VERSION ""

NS_ :

BS_:
BU_: Audio_Control_Module Audio_Interface_Module Bluetooth_Phone_Module Body_Electric_Module Front_Display_Interface_Module HVAC_Integrated_Module Instrustment_Cluster Parking_Aid_Module Powertrain_Control_Module Restraints_Control_Module Transmission_Control_Module On_Board_Diagnostics Antilock_Braking_System
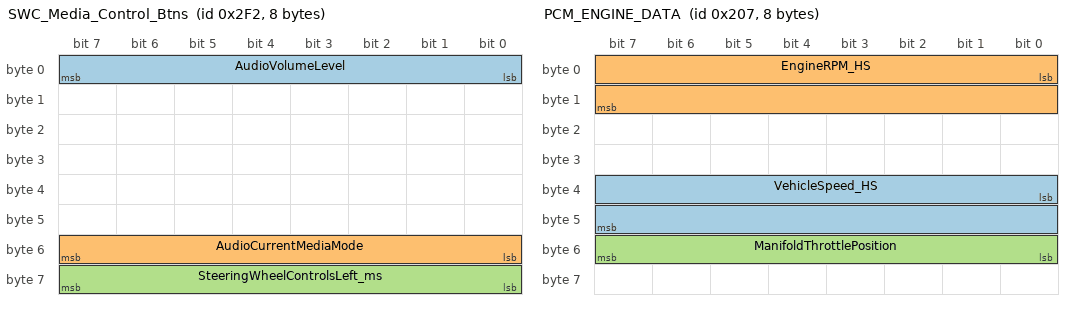
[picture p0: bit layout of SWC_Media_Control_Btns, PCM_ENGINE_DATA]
BO_ 754 SWC_Media_Control_Btns: 8 Front_Display_Interface_Module
   SG_ AudioVolumeLevel : 0|8@1+ (2,0) [0|15] "Vol" Audio_Control_Module
   SG_ AudioCurrentMediaMode : 48|8@1+ (1,0) [0|0] "" Audio_Control_Module
   SG_ SteeringWheelControlsLeft_ms : 56|8@1+ (1,0) [0|255] "ACTIVE/INACTIVE" Front_Display_Interface_Module

BO_ 764 Interior_Command_Centre_Btns: 8 Front_Display_Interface_Module
   SG_ SIGNAL38877 : 29|8@1+ (1,0) [0|255] "" Body_Electric_Module
   SG_ SIGNAL3887752 : 16|8@1+ (1,0) [0|255] "" Body_Electric_Module
   SG_ SIGNAL38877522 : 24|8@1+ (1,0) [0|255] "" Body_Electric_Module
   SG_ SIGNAL3887752238 : 8|8@1+ (1,0) [0|255] "" Body_Electric_Module

BO_ 751 MSG4: 8 Audio_Control_Module

BO_ 756 RDS_MESSAGE: 8 Audio_Control_Module
   SG_ RDS_MESSAGE0 : 0|8@4- (1,0) [0|255] "" Front_Display_Interface_Module
   SG_ RDS_MESSAGE1 : 8|8@4- (1,0) [0|255] "" Front_Display_Interface_Module
   SG_ RDS_MESSAGE2 : 16|8@4- (1,0) [0|255] "" Front_Display_Interface_Module
   SG_ RDS_MESSAGE3 : 24|8@4- (1,0) [0|255] "" Front_Display_Interface_Module
   SG_ RDS_MESSAGE4 : 32|8@4- (1,0) [0|255] "" Front_Display_Interface_Module
   SG_ RDS_MESSAGE5 : 40|8@4- (1,0) [0|255] "" Front_Display_Interface_Module
   SG_ RDS_MESSAGE6 : 48|8@4- (1,0) [0|255] "" Front_Display_Interface_Module
   SG_ RDS_MESSAGE7 : 56|8@4- (1,0) [0|255] "" Front_Display_Interface_Module

BO_ 757 RDS__MESSAGE: 8 Audio_Control_Module
   SG_ RDS_MESSAGE0 : 0|8@4- (1,0) [0|255] "" Front_Display_Interface_Module
   SG_ RDS_MESSAGE1 : 8|8@4- (1,0) [0|255] "" Front_Display_Interface_Module
   SG_ RDS_MESSAGE2 : 16|8@4- (1,0) [0|255] "" Front_Display_Interface_Module
   SG_ RDS_MESSAGE3 : 24|8@4- (1,0) [0|255] "" Front_Display_Interface_Module
   SG_ RDS_MESSAGE4 : 32|8@4- (1,0) [0|255] "" Front_Display_Interface_Module
   SG_ RDS_MESSAGE5 : 40|8@4- (1,0) [0|255] "" Front_Display_Interface_Module
   SG_ RDS_MESSAGE6 : 48|8@4- (1,0) [0|255] "" Front_Display_Interface_Module
   SG_ RDS_MESSAGE7 : 56|8@4- (1,0) [0|255] "" Front_Display_Interface_Module

BO_ 512 CrankStatusPCM_HS: 8 Powertrain_Control_Module
   SG_ CrankStatusPCM_HS : 0|8@1+ (1,0) [0|0] "" Powertrain_Control_Module

BO_ 519 PCM_ENGINE_DATA: 8 Powertrain_Control_Module
   SG_ VehicleSpeed_HS : 32|16@1+ (0.25,255) [0|260] "KM/H" Instrustment_Cluster
   SG_ EngineRPM_HS : 0|16@1+ (1,255) [0|8000] "RPM" Powertrain_Control_Module
   SG_ ManifoldThrottlePosition : 48|8@1+ (1,0) [0|100] "%" Powertrain_Control_Module

BO_ 528 ABS_DSC: 8 Antilock_Braking_System
   SG_ DSC : 16|8@1+ (1,0) [0|0] "" Antilock_Braking_System
   SG_ VDC_Failed : 0|8@1+ (1,0) [0|0] "" Antilock_Braking_System
   SG_ VDC_Event : 0|1@1+ (1,0) [0|0] "" Antilock_Braking_System
   SG_ VDC_DisabledByOperator : 24|1@1+ (1,0) [0|0] "" Antilock_Braking_System

BO_ 0 ABS_DSC: 8 Antilock_Braking_System
   SG_ ABSLF_I : 16|8@1+ (1,0) [0|0] "" Antilock_Braking_System
   SG_ ABSLF_I : 16|8@1+ (1,0) [0|0] "" Vector__XXX
   SG_ ABSLF_O : 16|8@1+ (1,0) [0|0] "" Vector__XXX
   SG_ ABSLR_I : 16|8@1+ (1,0) [0|0] "" Vector__XXX
   SG_ ABSLR_O : 16|8@1+ (1,0) [0|0] "" Vector__XXX
   SG_ ABSPMPRLY : 16|8@1+ (1,0) [0|0] "" Vector__XXX
   SG_ ABSRF_I : 16|8@1+ (1,0) [0|0] "" Vector__XXX
   SG_ ABSRF_O : 16|8@1+ (1,0) [0|0] "" Vector__XXX
   SG_ ABSRR_I : 16|8@1+ (1,0) [0|0] "" Vector__XXX
   SG_ ABSR_I : 16|8@1+ (1,0) [0|0] "" Vector__XXX
   SG_ ABSR_O : 16|8@1+ (1,0) [0|0] "" Vector__XXX
   SG_ ABSVLVRLY : 16|8@1+ (1,0) [0|0] "" Vector__XXX
   SG_ ABS_BYTE : 16|8@1+ (1,0) [0|0] "" Vector__XXX
   SG_ ABS_STAT : 16|8@1+ (1,0) [0|0] "" Vector__XXX
   SG_ BOO_ABS : 16|8@1+ (1,0) [0|0] "" Vector__XXX
   SG_ BRAKPRES : 16|8@1+ (1,0) [0|0] "" Vector__XXX
   SG_ CCNTABS : 16|8@1+ (1,0) [0|0] "" Vector__XXX
   SG_ DISABLE_SS : 16|8@1+ (1,0) [0|0] "" Vector__XXX
   SG_ HDC_ENABLE : 16|8@1+ (1,0) [0|0] "" Vector__XXX
   SG_ HDC_SW : 16|8@1+ (1,0) [0|0] "" Vector__XXX
   SG_ Ignition : 16|8@1+ (1,0) [0|0] "" Vector__XXX
   SG_ LAT_ACCL : 16|8@1+ (1,0) [0|0] "" Vector__XXX
   SG_ LF_WSPD : 16|8@1+ (1,0) [0|0] "" Vector__XXX
   SG_ LR_WSPD : 16|8@1+ (1,0) [0|0] "" Vector__XXX
   SG_ PMPSTAT : 16|8@1+ (1,0) [0|0] "" Vector__XXX
   SG_ PRK_BRAKE : 16|8@1+ (1,0) [0|0] "" Vector__XXX
   SG_ RF_WSPD : 16|8@1+ (1,0) [0|0] "" Vector__XXX
   SG_ RR_WSPD : 16|8@1+ (1,0) [0|0] "" Vector__XXX
   SG_ STEER_ANGL : 16|8@1+ (1,0) [0|0] "" Vector__XXX
   SG_ TCSPRI1 : 16|8@1+ (1,0) [0|0] "" Vector__XXX
   SG_ TCSPRI2 : 16|8@1+ (1,0) [0|0] "" Vector__XXX
   SG_ TCSSWI1 : 16|8@1+ (1,0) [0|0] "" Vector__XXX
   SG_ TCSSWI2 : 16|8@1+ (1,0) [0|0] "" Vector__XXX
   SG_ TCYC_FS : 16|8@1+ (1,0) [0|0] "" Vector__XXX
   SG_ TCYC_SW : 16|8@1+ (1,0) [0|0] "" Vector__XXX
   SG_ YAW_RATE : 16|8@1+ (1,0) [0|0] "" Vector__XXX

BO_ 560 TRANS: 8 Powertrain_Control_Module

BO_ 787 INTACTTEMP: 8 HVAC_Integrated_Module
   SG_ INTACTTEMP : 7|8@0+ (0.166667,0) [0|255] "Degrees_C" HVAC_Integrated_Module

BO_ 737 MSG1: 8 Front_Display_Interface_Module

BO_ 739 MSG2: 8 Front_Display_Interface_Module

BO_ 748 MSG3: 8 Front_Display_Interface_Module

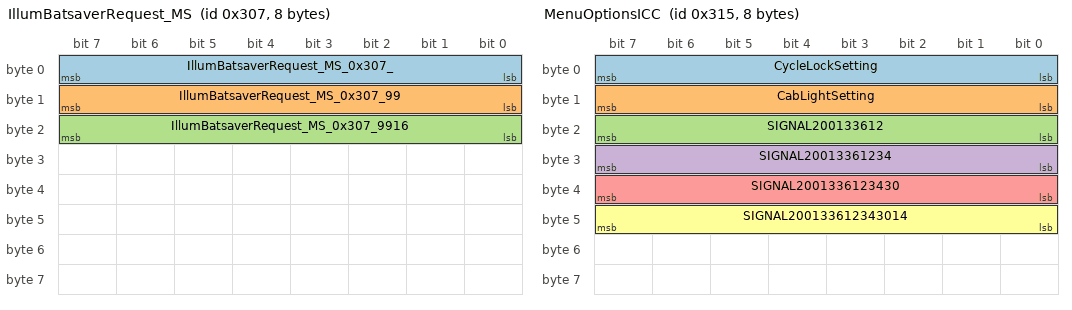
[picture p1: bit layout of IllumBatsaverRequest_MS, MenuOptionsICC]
BO_ 775 IllumBatsaverRequest_MS: 8 Body_Electric_Module
   SG_ IllumBatsaverRequest_MS_0x307_ : 0|8@1+ (1,0) [0|255] "" Body_Electric_Module
   SG_ IllumBatsaverRequest_MS_0x307_99 : 8|8@1+ (1,0) [0|0] "" Body_Electric_Module
   SG_ IllumBatsaverRequest_MS_0x307_9916 : 16|8@1+ (1,0) [0|255] "" Body_Electric_Module

BO_ 779 MSG6: 8 Body_Electric_Module

BO_ 781 CD_TRACK_TYPE_PLAYING: 8 Audio_Control_Module
   SG_ CD_TrackNumber : 0|8@1+ (1,0) [0|0] "" Front_Display_Interface_Module
   SG_ CD_Type : 0|8@1+ (1,0) [0|0] "" Front_Display_Interface_Module
   SG_ CD_PlayingNow : 0|8@1+ (1,0) [0|0] "" Front_Display_Interface_Module

BO_ 783 MSG8: 8 Body_Electric_Module

BO_ 785 MSG9: 8 Body_Electric_Module

BO_ 789 MenuOptionsICC: 8 Front_Display_Interface_Module
   SG_ CycleLockSetting : 0|8@1+ (1,0) [0|255] "" Front_Display_Interface_Module
   SG_ CabLightSetting : 8|8@1+ (1,0) [0|255] "" Front_Display_Interface_Module
   SG_ SIGNAL200133612 : 16|8@1+ (1,0) [0|255] "" Front_Display_Interface_Module
   SG_ SIGNAL20013361234 : 24|8@1+ (1,0) [0|255] "" Front_Display_Interface_Module
   SG_ SIGNAL2001336123430 : 32|8@1+ (1,0) [0|255] "" Front_Display_Interface_Module
   SG_ SIGNAL200133612343014 : 40|8@1+ (1,0) [0|255] "" Front_Display_Interface_Module

BO_ 791 VehicleIdentificationNumber: 8 Body_Electric_Module
   SG_ SIGNAL64904 : 0|8@1+ (1,0) [0|0] "" Body_Electric_Module
   SG_ SIGNAL11010 : 8|8@1+ (1,0) [0|0] "" Vector__XXX
   SG_ SIGNAL11074 : 8|8@1+ (1,0) [0|0] "" Vector__XXX
   SG_ SIGNAL61769 : 0|1@1+ (1,0) [0|0] "" Vector__XXX
   SG_ SIGNAL110107498 : 8|8@1+ (1,0) [0|0] "" Vector__XXX

BO_ 816 ParkBrakeOn_MS: 8 Body_Electric_Module
   SG_ ParkBrakeOn_MS : 0|8@1+ (1,0) [0|0] "" Body_Electric_Module

BO_ 1030 SeatBeltStatus: 8 Body_Electric_Module
   SG_ SeatBeltStatusFrontRight : 0|8@1+ (1,0) [0|0] "" Instrustment_Cluster
   SG_ SeatBeltStatusFrontLeft : 32|8@1+ (1,0) [0|0] "" Instrustment_Cluster
   SG_ SeatBeltStatusRearLeft : 16|8@1+ (1,0) [0|0] "" Instrustment_Cluster
   SG_ SeatBeltStatusRearRight : 24|8@1+ (1,0) [0|0] "" Instrustment_Cluster
   SG_ IgnitionState : 8|8@1+ (1,0) [0|0] "" Body_Electric_Module
   SG_ InteriorLightStatus : 0|8@1+ (1,0) [0|0] "" Body_Electric_Module

BO_ 1033 MSG14: 8 Body_Electric_Module

BO_ 1281 MSG15: 8 Body_Electric_Module

BO_ 1292 ACM_KeepAlive: 8 Audio_Control_Module

BO_ 1297 MSG17: 8 Body_Electric_Module

BO_ 1345 MSG18: 8 Body_Electric_Module

BO_ 1365 MSG19: 8 Body_Electric_Module

BO_ 1372 FDIM_KeepAlive: 8 Front_Display_Interface_Module

BO_ 1600 ManualTrans: 8 Body_Electric_Module
   SG_ ManualTrans : 0|8@1+ (1,0) [0|255] "" Instrustment_Cluster

BO_ 1782 ImmobTransfer_PCM_1_to_8_PATS: 8 Body_Electric_Module
   SG_ ImmobTransfer_PCM_1_to_8_PATS : 0|63@4- (1,0) [0|0] "" Body_Electric_Module

BO_ 1788 MSG23: 8 Body_Electric_Module

BO_ 301 EngineManagementData: 8 Powertrain_Control_Module
   SG_ AcceleratorPedalPosition1 : 8|8@1+ (0.5,0) [0|200] "%" Powertrain_Control_Module
   SG_ EngineRateOfChange0 : 0|8@1+ (1,0) [0|255] "" Powertrain_Control_Module
   SG_ AcceleratorPedalPosition2 : 16|8@1+ (0.5,0) [0|200] "%" Powertrain_Control_Module
   SG_ EngineRevolutionsPerMinute5 : 40|8@1+ (0.5,0) [0|0] "RPM" Powertrain_Control_Module
   SG_ EngineRevolutionsPerMinute4 : 32|8@1+ (1,255) [0|0] "RPM" Powertrain_Control_Module
   SG_ Flags : 48|8@1+ (1,0) [0|0] "" Powertrain_Control_Module
   SG_ BrakeHardwareStatus : 0|8@1+ (1,0) [0|1] "" Powertrain_Control_Module

BO_ 288 MSG1: 8 Powertrain_Control_Module
   SG_ TorqueReductionRequest : 0|8@1+ (1,0) [0|0] "" Powertrain_Control_Module

BO_ 1001 MSG2: 8 Powertrain_Control_Module

BO_ 1031 MSG3: 8 Powertrain_Control_Module

BO_ 1061 PCM_CRS_ECON: 8 Powertrain_Control_Module
   SG_ Cruise : 0|1@1+ (1,0) [0|0] "" Powertrain_Control_Module
   SG_ CruiseTargetSetSpeed : 0|1@1+ (1,0) [0|0] "" Powertrain_Control_Module
   SG_ InstantEconomy : 0|1@1+ (1,0) [0|0] "" Powertrain_Control_Module
   SG_ InstantEconomyMode : 0|1@1+ (1,0) [0|0] "" Powertrain_Control_Module
   SG_ TurboBoostPressure : 0|1@1+ (1,0) [0|0] "" Powertrain_Control_Module

BO_ 1063 PCM_ENGINE_DATA: 8 Powertrain_Control_Module
   SG_ EngineCoolantTemperature : 0|8@1+ (0.5,0) [0|255] "Degrees_C" Powertrain_Control_Module
   SG_ EngineOverheat : 40|8@1+ (1,0) [0|0] "" Powertrain_Control_Module
   SG_ OilPressureWarning : 40|8@1+ (1,0) [0|0] "" Powertrain_Control_Module
   SG_ ETC_Warning : 40|8@1+ (1,0) [0|0] "" Powertrain_Control_Module
   SG_ FuelPulse : 0|1@1+ (1,0) [0|0] "" Powertrain_Control_Module
   SG_ MIL_Lamp : 40|8@1+ (1,0) [0|0] "" Powertrain_Control_Module
   SG_ AC_Pressure : 8|16@1+ (1,0) [0|255] "KPa" Powertrain_Control_Module
   SG_ ImmobLamp : 48|8@1+ (1,0) [0|0] "" Powertrain_Control_Module
   SG_ SEATBELT_INDICATOR_STAT : 48|8@1+ (1,0) [0|0] "" Powertrain_Control_Module
   SG_ ODO_COUNT : 32|8@1+ (1,0) [0|255] "" Powertrain_Control_Module
   SG_ BatteryVoltage : 24|8@1+ (0.1,0) [0|255] "Volts" Body_Electric_Module
   SG_ EngineSpeedCounter : 56|8@1+ (1,0) [0|255] "Count" Powertrain_Control_Module

BO_ 1079 PCM_: 8 Powertrain_Control_Module
   SG_ InstFuelValue : 0|1@1+ (1,0) [0|0] "" Powertrain_Control_Module
   SG_ FuelSenderFail : 0|1@1+ (1,0) [0|0] "" Powertrain_Control_Module
   SG_ ParkBrakeOn_HS : 32|1@1+ (1,0) [0|0] "" Powertrain_Control_Module
   SG_ MaxLitres : 0|1@1+ (1,0) [0|0] "" Powertrain_Control_Module
   SG_ DampedFuelLevel : 0|1@1+ (1,0) [0|0] "" Powertrain_Control_Module

BO_ 1101 PCM_EOT_: 8 Powertrain_Control_Module

BO_ 1107 ODO: 8 Powertrain_Control_Module

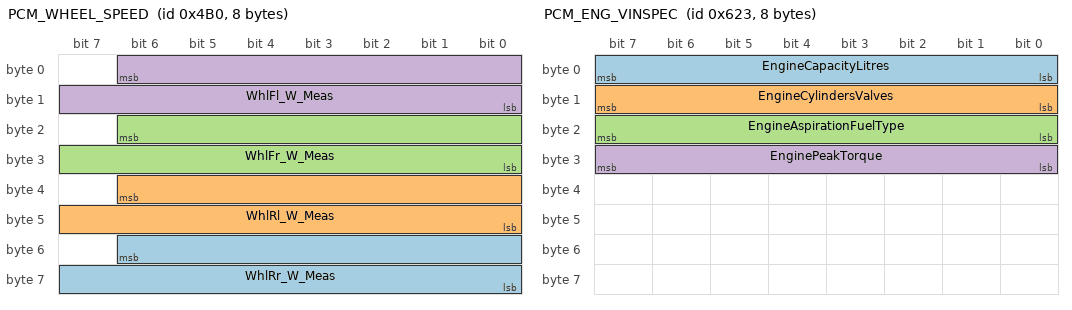
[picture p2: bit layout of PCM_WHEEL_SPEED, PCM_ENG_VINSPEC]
BO_ 1200 PCM_WHEEL_SPEED: 8 Antilock_Braking_System
   SG_ WhlRr_W_Meas : 54|15@0+ (0.01,0) [0|327.65] "rad/s" Powertrain_Control_Module
   SG_ WhlRl_W_Meas : 38|15@0+ (0.01,0) [0|327.65] "rad/s" Powertrain_Control_Module
   SG_ WhlFr_W_Meas : 22|15@0+ (0.01,0) [0|327.65] "rad/s" Powertrain_Control_Module
   SG_ WhlFl_W_Meas : 6|15@0+ (0.01,0) [0|327.65] "rad/s" Powertrain_Control_Module

BO_ 76 PCM_: 0 Powertrain_Control_Module

BO_ 1216 MSG1: 8 Powertrain_Control_Module

BO_ 1571 PCM_ENG_VINSPEC: 8 Powertrain_Control_Module
   SG_ EngineCapacityLitres : 0|8@1+ (0.1,0) [0|0] "Litres" Powertrain_Control_Module
   SG_ EngineCylindersValves : 8|8@1+ (1,0) [0|0] "" Powertrain_Control_Module
   SG_ EngineAspirationFuelType : 16|8@1+ (1,0) [0|0] "" Powertrain_Control_Module
   SG_ EnginePeakTorque : 24|8@1+ (4,1) [0|0] "NM" Powertrain_Control_Module

BO_ 1616 MSG1: 8 Powertrain_Control_Module

BO_ 1784 MSG2: 8 Powertrain_Control_Module

BO_ 2024 On_Board_Diagnostics: 8 On_Board_Diagnostics
   SG_ S1_PID_00_PIDsSupported_01_20 m0 : 23|32@0+ (1,0) [0|4.29497e+09] "" On_Board_Diagnostics
   SG_ S1_PID_01_MonitorStatus m1 : 31|32@0+ (1,0) [0|4.29497e+09] "" On_Board_Diagnostics
   SG_ S1_PID_02_FreezeDTC m2 : 31|16@0+ (1,0) [0|65535] "" On_Board_Diagnostics
   SG_ S1_PID_03_FuelSystemStatus m3 : 31|16@0+ (1,0) [0|65535] "" On_Board_Diagnostics
   SG_ S1_PID_04_CalcEngineLoad m4 : 31|8@0+ (0.39216,0) [0|100] "%" On_Board_Diagnostics
   SG_ S1_PID_05_EngineCoolantTemp m5 : 31|8@0+ (1,-40) [-40|215] "degC" On_Board_Diagnostics
   SG_ S1_PID_06_ShortFuelTrimBank1 m6 : 31|8@0+ (0.78125,-100) [-100|99.2188] "%" On_Board_Diagnostics
   SG_ S1_PID_07_LongFuelTrimBank1 m7 : 31|8@0+ (0.78125,-100) [-100|99.2188] "%" On_Board_Diagnostics
   SG_ S1_PID_08_ShortFuelTrimBank2 m8 : 31|8@0+ (0.78125,-100) [-100|99.2188] "%" On_Board_Diagnostics
   SG_ S1_PID_09_LongFuelTrimBank2 m9 : 31|8@0+ (0.78125,-100) [-100|99.2188] "%" On_Board_Diagnostics
   SG_ S1_PID_0A_FuelPressure m10 : 31|8@0+ (3,0) [0|765] "kPa" On_Board_Diagnostics
   SG_ S1_PID_0B_IntakeManiAbsPress m11 : 31|8@0+ (1,0) [0|255] "kPa" On_Board_Diagnostics
   SG_ S1_PID_0C_EngineRPM m12 : 31|16@0+ (0.25,0) [0|16383.8] "rpm" On_Board_Diagnostics
   SG_ S1_PID_0D_VehicleSpeed m13 : 31|8@0+ (1,0) [0|255] "km/h" On_Board_Diagnostics
   SG_ S1_PID_0E_TimingAdvance m14 : 31|8@0+ (0.5,-64) [-64|63.5] "deg before TDC" On_Board_Diagnostics
   SG_ S1_PID_0F_IntakeAirTemperature m15 : 31|8@0+ (1,-40) [-40|215] "degC" On_Board_Diagnostics
   SG_ S1_PID_10_MAFAirFlowRate m16 : 31|16@0+ (0.01,0) [0|655.35] "grams/sec" On_Board_Diagnostics
   SG_ S1_PID_11_ThrottlePosition m17 : 31|8@0+ (0.39216,0) [0|100] "%" On_Board_Diagnostics
   SG_ S1_PID_12_CmdSecAirStatus m18 : 31|8@0+ (1,0) [0|255] "" On_Board_Diagnostics
   SG_ S1_PID_14_OxySensor1_Volt m20 : 31|8@0+ (0.005,0) [0|1.275] "volts" On_Board_Diagnostics
   SG_ S1_PID_14_OxySensor1_STFT m20 : 39|8@0+ (0.78125,-100) [-100|99.2188] "%" On_Board_Diagnostics
   SG_ S1_PID_15_OxySensor2_Volt m21 : 31|8@0+ (0.005,0) [0|1.275] "volts" On_Board_Diagnostics
   SG_ S1_PID_15_OxySensor2_STFT m21 : 39|8@0+ (0.78125,-100) [-100|99.2188] "%" On_Board_Diagnostics
   SG_ S1_PID_16_OxySensor3_Volt m22 : 31|8@0+ (0.005,0) [0|1.275] "volts" On_Board_Diagnostics
   SG_ S1_PID_16_OxySensor3_STFT m22 : 39|8@0+ (0.78125,-100) [-100|99.2188] "%" On_Board_Diagnostics
   SG_ S1_PID_17_OxySensor4_Volt m23 : 31|8@0+ (0.005,0) [0|1.275] "volts" On_Board_Diagnostics
   SG_ S1_PID_17_OxySensor4_STFT m23 : 39|8@0+ (0.78125,-100) [-100|99.2188] "%" On_Board_Diagnostics
   SG_ S1_PID_18_OxySensor5_Volt m24 : 31|8@0+ (0.005,0) [0|1.275] "volts" On_Board_Diagnostics
   SG_ S1_PID_18_OxySensor5_STFT m24 : 39|8@0+ (0.78125,-100) [-100|99.2188] "%" On_Board_Diagnostics
   SG_ S1_PID_19_OxySensor6_Volt m25 : 31|8@0+ (0.005,0) [0|1.275] "volts" On_Board_Diagnostics
   SG_ S1_PID_19_OxySensor6_STFT m25 : 39|8@0+ (0.78125,-100) [-100|99.2188] "%" On_Board_Diagnostics
   SG_ S1_PID_1A_OxySensor7_Volt m26 : 31|8@0+ (0.005,0) [0|1.275] "volts" On_Board_Diagnostics
   SG_ S1_PID_1A_OxySensor7_STFT m26 : 39|8@0+ (0.78125,-100) [-100|99.2188] "%" On_Board_Diagnostics
   SG_ S1_PID_1B_OxySensor8_Volt m27 : 31|8@0+ (0.005,0) [0|1.275] "volts" On_Board_Diagnostics
   SG_ S1_PID_1B_OxySensor8_STFT m27 : 39|8@0+ (0.78125,-100) [-100|99.2188] "%" On_Board_Diagnostics
   SG_ S1_PID_1C_OBDStandard m28 : 31|8@0+ (1,0) [0|255] "" On_Board_Diagnostics
   SG_ S1_PID_1F_TimeSinceEngStart m31 : 31|16@0+ (1,0) [0|65535] "seconds" On_Board_Diagnostics
   SG_ S1_PID_20_PIDsSupported_21_40 m32 : 31|32@0+ (1,0) [0|4.29497e+09] "" On_Board_Diagnostics
   SG_ S1_PID_21_DistanceMILOn m33 : 31|16@0+ (1,0) [0|65535] "km" On_Board_Diagnostics
   SG_ S1_PID_22_FuelRailPres m34 : 31|16@0+ (0.079,0) [0|5177.27] "kPa" On_Board_Diagnostics
   SG_ S1_PID_23_FuelRailGaug m35 : 31|16@0+ (10,0) [0|655350] "kPa" On_Board_Diagnostics
   SG_ S1_PID_24_OxySensor1_FAER m36 : 31|16@0+ (3.05176e-05,0) [0|2] "ratio" On_Board_Diagnostics
   SG_ S1_PID_24_OxySensor1_Volt m36 : 47|16@0+ (0.00012207,0) [0|2] "volts" On_Board_Diagnostics
   SG_ S1_PID_25_OxySensor2_FAER m37 : 31|16@0+ (3.05176e-05,0) [0|2] "ratio" On_Board_Diagnostics
   SG_ S1_PID_25_OxySensor2_Volt m37 : 47|16@0+ (0.00012207,0) [0|8] "volts" On_Board_Diagnostics
   SG_ S1_PID_26_OxySensor3_FAER m38 : 31|16@0+ (3.05176e-05,0) [0|2] "ratio" On_Board_Diagnostics
   SG_ S1_PID_26_OxySensor3_Volt m38 : 47|16@0+ (0.00012207,0) [0|8] "volts" On_Board_Diagnostics
   SG_ S1_PID_27_OxySensor4_FAER m39 : 31|16@0+ (3.05176e-05,0) [0|2] "ratio" On_Board_Diagnostics
   SG_ S1_PID_27_OxySensor4_Volt m39 : 47|16@0+ (0.00012207,0) [0|8] "volts" On_Board_Diagnostics
   SG_ S1_PID_28_OxySensor5_FAER m40 : 31|16@0+ (3.05176e-05,0) [0|2] "ratio" On_Board_Diagnostics
   SG_ S1_PID_28_OxySensor5_Volt m40 : 47|16@0+ (0.00012207,0) [0|8] "volts" On_Board_Diagnostics
   SG_ S1_PID_29_OxySensor6_FAER m41 : 31|16@0+ (3.05176e-05,0) [0|2] "ratio" On_Board_Diagnostics
   SG_ S1_PID_29_OxySensor6_Volt m41 : 47|16@0+ (0.00012207,0) [0|8] "volts" On_Board_Diagnostics
   SG_ S1_PID_2A_OxySensor7_FAER m42 : 31|16@0+ (3.05176e-05,0) [0|2] "ratio" On_Board_Diagnostics
   SG_ S1_PID_2A_OxySensor7_Volt m42 : 47|16@0+ (0.00012207,0) [0|8] "volts" On_Board_Diagnostics
   SG_ S1_PID_2B_OxySensor8_FAER m43 : 31|16@0+ (3.05176e-05,0) [0|2] "ratio" On_Board_Diagnostics
   SG_ S1_PID_2B_OxySensor8_Volt m43 : 47|16@0+ (0.00012207,0) [0|8] "volts" On_Board_Diagnostics
   SG_ S1_PID_2E_CmdEvapPurge m46 : 31|8@0+ (0.392157,0) [0|100] "%" On_Board_Diagnostics
   SG_ S1_PID_2F_FuelTankLevel m47 : 31|8@0+ (0.392157,0) [0|100] "%" On_Board_Diagnostics
   SG_ S1_PID_30_WarmUpsSinceCodeClear m48 : 31|8@0+ (1,0) [0|255] "count" On_Board_Diagnostics
   SG_ S1_PID_31_DistanceSinceCodeClear m49 : 31|16@0+ (1,0) [0|65535] "km" On_Board_Diagnostics
   SG_ S1_PID_32_EvapSysVaporPres m50 : 31|16@0- (0.25,0) [-8192|8191.75] "Pa" On_Board_Diagnostics
   SG_ S1_PID_33_AbsBaroPres m51 : 31|8@0+ (1,0) [0|255] "kPa" On_Board_Diagnostics
   SG_ S1_PID_34_OxySensor1_FAER m52 : 31|16@0+ (3.05176e-05,0) [0|2] "ratio" On_Board_Diagnostics
   SG_ S1_PID_34_OxySensor1_Crnt m52 : 47|16@0+ (0.00390625,-128) [-128|128] "mA" On_Board_Diagnostics
   SG_ S1_PID_35_OxySensor2_FAER m53 : 31|16@0+ (3.05176e-05,0) [0|2] "ratio" On_Board_Diagnostics
   SG_ S1_PID_35_OxySensor2_Crnt m53 : 47|16@0+ (0.00390625,-128) [-128|128] "mA" On_Board_Diagnostics
   SG_ S1_PID_36_OxySensor3_FAER m54 : 31|16@0+ (3.05176e-05,0) [0|2] "ratio" On_Board_Diagnostics
   SG_ S1_PID_36_OxySensor3_Crnt m54 : 47|16@0+ (0.00390625,-128) [-128|128] "mA" On_Board_Diagnostics
   SG_ S1_PID_37_OxySensor4_FAER m55 : 31|16@0+ (3.05176e-05,0) [0|2] "ratio" On_Board_Diagnostics
   SG_ S1_PID_37_OxySensor4_Crnt m55 : 47|16@0+ (0.00390625,-128) [-128|128] "mA" On_Board_Diagnostics
   SG_ S1_PID_38_OxySensor5_FAER m56 : 31|16@0+ (3.05176e-05,0) [0|2] "ratio" On_Board_Diagnostics
   SG_ S1_PID_38_OxySensor5_Crnt m56 : 47|16@0+ (0.00390625,-128) [-128|128] "mA" On_Board_Diagnostics
   SG_ S1_PID_39_OxySensor6_FAER m57 : 31|16@0+ (3.05176e-05,0) [0|2] "ratio" On_Board_Diagnostics
   SG_ S1_PID_39_OxySensor6_Crnt m57 : 47|16@0+ (0.00390625,-128) [-128|128] "mA" On_Board_Diagnostics
   SG_ S1_PID_3A_OxySensor7_FAER m58 : 31|16@0+ (3.05176e-05,0) [0|2] "ratio" On_Board_Diagnostics
   SG_ S1_PID_3A_OxySensor7_Crnt m58 : 47|16@0+ (0.00390625,-128) [-128|128] "mA" On_Board_Diagnostics
   SG_ S1_PID_3B_OxySensor8_FAER m59 : 31|16@0+ (3.05176e-05,0) [0|2] "ratio" On_Board_Diagnostics
   SG_ S1_PID_3B_OxySensor8_Crnt m59 : 47|16@0+ (0.00390625,-128) [-128|128] "mA" On_Board_Diagnostics
   SG_ S1_PID_3C_CatTempBank1Sens1 m60 : 31|16@0+ (0.1,-40) [-40|6513.5] "degC" On_Board_Diagnostics
   SG_ S1_PID_3D_CatTempBank2Sens1 m61 : 31|16@0+ (0.1,-40) [-40|6513.5] "degC" On_Board_Diagnostics
   SG_ S1_PID_3E_CatTempBank1Sens2 m62 : 31|16@0+ (0.1,-40) [-40|6513.5] "degC" On_Board_Diagnostics
   SG_ S1_PID_3F_CatTempBank2Sens2 m63 : 31|16@0+ (0.1,-40) [-40|6513.5] "degC" On_Board_Diagnostics
   SG_ S1_PID_40_PIDsSupported_41_60 m64 : 31|32@0+ (1,0) [0|4.29497e+09] "" On_Board_Diagnostics
   SG_ S1_PID_41_MonStatusDriveCycle m65 : 31|32@0+ (1,0) [0|4.29497e+09] "" On_Board_Diagnostics
   SG_ S1_PID_42_ControlModuleVolt m66 : 31|16@0+ (0.001,0) [0|65.535] "V" On_Board_Diagnostics
   SG_ S1_PID_43_AbsLoadValue m67 : 31|16@0+ (0.392157,0) [0|25700] "%" On_Board_Diagnostics
   SG_ S1_PID_44_FuelAirCmdEquiv m68 : 31|16@0+ (3.05176e-05,0) [0|2] "ratio" On_Board_Diagnostics
   SG_ S1_PID_45_RelThrottlePos m69 : 31|8@0+ (0.392157,0) [0|100] "%" On_Board_Diagnostics
   SG_ S1_PID_46_AmbientAirTemp m70 : 31|8@0+ (1,-40) [-40|215] "degC" On_Board_Diagnostics
   SG_ S1_PID_47_AbsThrottlePosB m71 : 31|8@0+ (0.392157,0) [0|100] "%" On_Board_Diagnostics
   SG_ S1_PID_48_AbsThrottlePosC m72 : 31|8@0+ (0.392157,0) [0|100] "%" On_Board_Diagnostics
   SG_ S1_PID_49_AbsThrottlePosD m73 : 31|8@0+ (0.392157,0) [0|100] "%" On_Board_Diagnostics
   SG_ S1_PID_4A_AbsThrottlePosE m74 : 31|8@0+ (0.392157,0) [0|100] "%" On_Board_Diagnostics
   SG_ S1_PID_4B_AbsThrottlePosF m75 : 31|8@0+ (0.392157,0) [0|100] "%" On_Board_Diagnostics
   SG_ S1_PID_4C_CmdThrottleAct m76 : 31|8@0+ (0.392157,0) [0|100] "%" On_Board_Diagnostics
   SG_ S1_PID_4D_TimeRunMILOn m77 : 31|16@0+ (1,0) [0|65535] "minutes" On_Board_Diagnostics
   SG_ S1_PID_4E_TimeSinceCodeClear m78 : 31|16@0+ (1,0) [0|65535] "minutes" On_Board_Diagnostics
   SG_ S1_PID_4F_Max_FAER m79 : 31|8@0+ (1,0) [0|255] "ratio" On_Board_Diagnostics
   SG_ S1_PID_4F_Max_OxySensVol m79 : 39|8@0+ (1,0) [0|255] "V" On_Board_Diagnostics
   SG_ S1_PID_4F_Max_OxySensCrnt m79 : 47|8@0+ (1,0) [0|255] "mA" On_Board_Diagnostics
   SG_ S1_PID_4F_Max_IntManiAbsPres m79 : 55|8@0+ (10,0) [0|2550] "kPa" On_Board_Diagnostics
   SG_ S1_PID_50_Max_AirFlowMAF m80 : 31|8@0+ (10,0) [0|2550] "g/s" On_Board_Diagnostics
   SG_ S1_PID_51_FuelType m81 : 31|8@0+ (1,0) [0|255] "" On_Board_Diagnostics
   SG_ S1_PID_52_EthanolFuelPct m82 : 31|8@0+ (0.392157,0) [0|100] "%" On_Board_Diagnostics
   SG_ S1_PID_53_AbsEvapSysVapPres m83 : 31|16@0+ (0.005,0) [0|327.675] "kPa" On_Board_Diagnostics
   SG_ S1_PID_54_EvapSysVapPres m84 : 31|16@0+ (1,-32767) [-32767|32768] "Pa" On_Board_Diagnostics
   SG_ S1_PID_55_ShortSecOxyTrimBank1 m85 : 31|8@0+ (0.78125,-100) [-100|99.2188] "%" On_Board_Diagnostics
   SG_ S1_PID_55_ShortSecOxyTrimBank3 m85 : 39|8@0+ (0.78125,-100) [-100|99.2188] "%" On_Board_Diagnostics
   SG_ S1_PID_56_LongSecOxyTrimBank1 m86 : 31|8@0+ (0.78125,-100) [-100|99.2188] "%" On_Board_Diagnostics
   SG_ S1_PID_56_LongSecOxyTrimBank3 m86 : 39|8@0+ (0.78125,-100) [-100|99.2188] "%" On_Board_Diagnostics
   SG_ S1_PID_57_ShortSecOxyTrimBank2 m87 : 31|8@0+ (0.78125,-100) [-100|99.2188] "%" On_Board_Diagnostics
   SG_ S1_PID_57_ShortSecOxyTrimBank4 m87 : 39|8@0+ (0.78125,-100) [-100|99.2188] "%" On_Board_Diagnostics
   SG_ S1_PID_58_LongSecOxyTrimBank2 m88 : 31|8@0+ (0.78125,-100) [-100|99.2188] "%" On_Board_Diagnostics
   SG_ S1_PID_58_LongSecOxyTrimBank4 m88 : 39|8@0+ (0.78125,-100) [-100|99.2188] "%" On_Board_Diagnostics
   SG_ S1_PID_59_FuelRailAbsPres m89 : 31|16@0+ (10,0) [0|655350] "kPa" On_Board_Diagnostics
   SG_ S1_PID_5A_RelAccelPedalPos m90 : 31|8@0+ (0.392157,0) [0|100] "%" On_Board_Diagnostics
   SG_ S1_PID_5C_EngineOilTemp m92 : 31|8@0+ (1,-40) [-40|215] "degC" On_Board_Diagnostics
   SG_ S1_PID_5D_FuelInjectionTiming m93 : 31|16@0+ (0.0078125,-210) [-210|301.992] "deg" On_Board_Diagnostics
   SG_ S1_PID_5E_EngineFuelRate m94 : 31|16@0+ (0.05,0) [0|3276.75] "L/h" On_Board_Diagnostics
   SG_ S1_PID_5F_EmissionReq m95 : 31|8@0+ (1,0) [0|255] "" On_Board_Diagnostics
   SG_ S1_PID_60_PIDsSupported_61_80 m96 : 31|32@0+ (1,0) [0|4.29497e+09] "" On_Board_Diagnostics
   SG_ S1_PID_61_DemandEngTorqPct m97 : 31|8@0+ (1,-125) [-125|130] "%" On_Board_Diagnostics
   SG_ S1_PID_62_ActualEngTorqPct m98 : 31|8@0+ (1,-125) [-125|130] "%" On_Board_Diagnostics
   SG_ S1_PID_63_EngRefTorq m99 : 31|16@0+ (1,0) [0|65535] "Nm" On_Board_Diagnostics
   SG_ S1_PID_64_EngPctTorq_Idle m100 : 31|8@0+ (1,-125) [-125|130] "%" On_Board_Diagnostics
   SG_ S1_PID_64_EngPctTorq_EP1 m100 : 39|8@0+ (1,-125) [-125|130] "%" On_Board_Diagnostics
   SG_ S1_PID_64_EngPctTorq_EP2 m100 : 47|8@0+ (1,-125) [-125|130] "%" On_Board_Diagnostics
   SG_ S1_PID_64_EngPctTorq_EP3 m100 : 55|8@0+ (1,-125) [-125|130] "%" On_Board_Diagnostics
   SG_ S1_PID_64_EngPctTorq_EP4 m100 : 63|8@0+ (1,-125) [-125|130] "%" On_Board_Diagnostics
   SG_ S1_PID_65_AuxInputOutput m101 : 31|8@0+ (1,0) [0|255] "" On_Board_Diagnostics
   SG_ S1_PID_66_MAFSensor m102 : 31|8@0+ (1,0) [0|255] "" On_Board_Diagnostics
   SG_ S1_PID_67_EngineCoolantTemp m103 : 31|8@0+ (1,0) [0|255] "" On_Board_Diagnostics
   SG_ S1_PID_68_IntakeAirTempSens m104 : 31|8@0+ (1,0) [0|255] "" On_Board_Diagnostics
   SG_ S1_PID_6B_ExhaustGasTemp m107 : 31|8@0+ (1,0) [0|255] "" On_Board_Diagnostics
   SG_ S1_PID_6C_CmdThrottleActRel m108 : 31|8@0+ (1,0) [0|255] "" On_Board_Diagnostics
   SG_ S1_PID_6D_FuelPresContrSys m109 : 31|8@0+ (1,0) [0|255] "" On_Board_Diagnostics
   SG_ S1_PID_6E_InjPresContrSys m110 : 31|8@0+ (1,0) [0|255] "" On_Board_Diagnostics
   SG_ S1_PID_6F_TurboComprPres m111 : 31|8@0+ (1,0) [0|255] "" On_Board_Diagnostics
   SG_ S1_PID_70_BoostPresCntrl m112 : 31|8@0+ (1,0) [0|255] "" On_Board_Diagnostics
   SG_ S1_PID_80_PIDsSupported_81_A0 m128 : 31|32@0+ (1,0) [0|4.29497e+09] "" On_Board_Diagnostics
   SG_ S1_PID_8E_EngFrictionPctTorq m142 : 31|8@0+ (1,-125) [-125|130] "%" On_Board_Diagnostics
   SG_ S1_PID_A0_PIDsSupported_A1_C0 m160 : 31|32@0+ (1,0) [0|4.29497e+09] "" On_Board_Diagnostics
   SG_ S1_PID_C0_PIDsSupported_C1_E0 m192 : 31|32@0+ (1,0) [0|4.29497e+09] "" On_Board_Diagnostics
   SG_ S2_PID_02_FreezeDTC m2 : 31|16@0+ (1,0) [0|65535] "" On_Board_Diagnostics
   SG_ service M : 11|4@0+ (1,0) [0|15] "" On_Board_Diagnostics
   SG_ response : 15|4@0+ (1,0) [0|15] "" On_Board_Diagnostics
   SG_ length : 7|8@0+ (1,0) [0|255] "" On_Board_Diagnostics

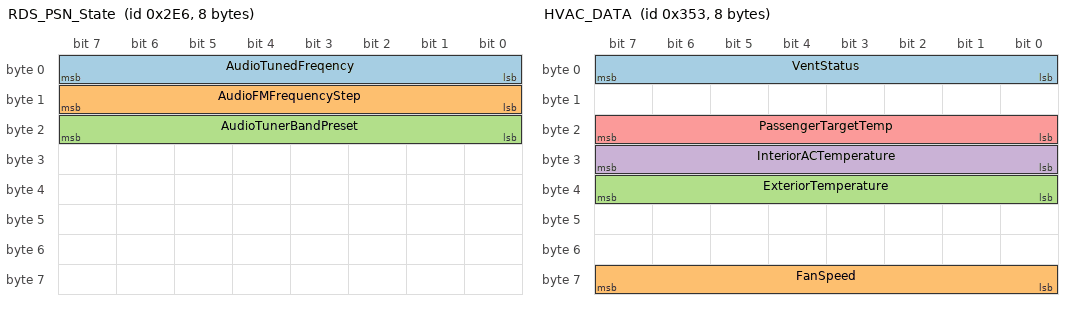
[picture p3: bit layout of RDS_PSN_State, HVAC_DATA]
BO_ 742 RDS_PSN_State: 8 Audio_Control_Module
   SG_ AudioTunedFreqency : 0|8@1+ (2,0) [0|255] "" Front_Display_Interface_Module
   SG_ AudioFMFrequencyStep : 8|8@1+ (0.01,0) [0|255] "" Front_Display_Interface_Module
   SG_ AudioTunerBandPreset : 16|8@1+ (1,0) [0|255] "" Front_Display_Interface_Module
   SG_ RDS_PSN_State : 0|1@4- (1,0) [0|0] "" Front_Display_Interface_Module

BO_ 758 RDS___MESSAGE: 8 Audio_Control_Module
   SG_ RDS_MESSAGE0 : 0|8@4- (1,0) [0|255] "" Front_Display_Interface_Module
   SG_ RDS_MESSAGE1 : 8|8@4- (1,0) [0|255] "" Front_Display_Interface_Module
   SG_ RDS_MESSAGE2 : 16|8@4- (1,0) [0|255] "" Front_Display_Interface_Module
   SG_ RDS_MESSAGE3 : 24|8@4- (1,0) [0|255] "" Front_Display_Interface_Module
   SG_ RDS_MESSAGE4 : 32|8@4- (1,0) [0|255] "" Front_Display_Interface_Module
   SG_ RDS_MESSAGE5 : 40|8@4- (1,0) [0|255] "" Front_Display_Interface_Module
   SG_ RDS_MESSAGE6 : 48|8@4- (1,0) [0|255] "" Front_Display_Interface_Module
   SG_ RDS_MESSAGE7 : 56|8@4- (1,0) [0|255] "" Front_Display_Interface_Module

BO_ 714 MSG1: 8 Bluetooth_Phone_Module
   SG_ BTH_CONTD : 0|8@4- (1,0) [0|255] "" Bluetooth_Phone_Module
   SG_ CCNT : 0|8@4- (1,0) [0|255] "" Bluetooth_Phone_Module
   SG_ ECU : 0|8@4- (1,0) [0|255] "" Bluetooth_Phone_Module
   SG_ ONDEMDTC : 0|8@4- (1,0) [0|255] "" Bluetooth_Phone_Module
   SG_ SEC_STAT_BPM : 0|8@4- (1,0) [0|255] "" Bluetooth_Phone_Module

BO_ 864 ReverseSenseSystem: 8 Parking_Aid_Module
   SG_ PARK_SYS : 0|8@1+ (1,0) [0|0] "" Parking_Aid_Module
   SG_ RC_DIST : 8|8@1+ (1,0) [0|0] "" Parking_Aid_Module
   SG_ REAR_SENS : 58|8@1+ (1,0) [0|0] "" Parking_Aid_Module
   SG_ REAR_TONE : 40|8@1+ (1,0) [0|0] "" Parking_Aid_Module
   SG_ RM_DIST : 24|8@1+ (1,0) [0|0] "" Parking_Aid_Module
   SG_ SENSOR_SPL_V : 32|8@1+ (1,0) [0|0] "" Parking_Aid_Module
   SG_ SPEED_DEACT : 48|8@1+ (1,0) [0|0] "" Parking_Aid_Module
   SG_ SYS_OZ : 16|8@1+ (1,0) [0|0] "" Parking_Aid_Module
   SG_ TRAILINS : 0|8@1+ (1,0) [0|0] "" Parking_Aid_Module
   SG_ TRANSRV : 0|8@1+ (1,0) [0|0] "" Parking_Aid_Module
   SG_ VBAT : 0|8@1+ (1,0) [0|0] "" Parking_Aid_Module

BO_ 1027 MSG1: 0 Front_Display_Interface_Module

BO_ 1824 IC_DiagSig_Rx: 8 Instrustment_Cluster
   SG_ SIGNAL33396 : 0|8@1+ (1,0) [0|0] "" Vector__XXX

BO_ 296 Instrument_Cluster: 8 Instrustment_Cluster
   SG_ HighBeamStatus : 0|1@1+ (1,0) [0|0] "" Vector__XXX
   SG_ FogLampStatus : 0|1@1+ (1,0) [0|0] "" Vector__XXX
   SG_ ParkAndLowBeamStatus : 0|1@1+ (1,0) [0|0] "" Vector__XXX
   SG_ AutoHeadlampSwitchStatus : 0|1@1+ (1,0) [0|0] "" Vector__XXX
   SG_ IllumLevelDisplay : 0|1@1+ (1,0) [0|0] "" Vector__XXX
   SG_ IllumLevelSwitch : 0|8@1+ (1,0) [0|0] "" Body_Electric_Module
   SG_ TurnStalkSwitchSatus : 16|8@1+ (1,0) [0|0] "" Vector__XXX
   SG_ RearBeltMinderStatus : 0|1@1+ (1,0) [0|0] "" Vector__XXX

BO_ 851 HVAC_DATA: 8 HVAC_Integrated_Module
   SG_ VentStatus : 0|8@1+ (1,0) [0|0] "" HVAC_Integrated_Module
   SG_ FanSpeed : 56|8@1+ (1,0) [0|0] "" HVAC_Integrated_Module
   SG_ ExteriorTemperature : 32|8@1+ (1,0) [0|0] "" HVAC_Integrated_Module
   SG_ InteriorACTemperature : 24|8@1+ (1,0) [0|0] "Degrees_C" HVAC_Integrated_Module
   SG_ PassengerTargetTemp : 16|8@1+ (1,0) [0|0] "" HVAC_Integrated_Module

BO_ 39321 IPOD_: 8 Audio_Interface_Module
   SG_ AUTHENT_DEVER : 0|8@1+ (1,0) [0|0] "" Audio_Interface_Module
   SG_ CON_DEVERR : 0|8@1+ (1,0) [0|0] "" Audio_Interface_Module
   SG_ CON_DEVMODID : 0|8@1+ (1,0) [0|0] "" Audio_Interface_Module
   SG_ IPOD_FRMVER : 0|8@1+ (1,0) [0|0] "" Audio_Interface_Module
   SG_ NUM_DTC : 0|8@1+ (1,0) [0|0] "" Audio_Interface_Module
   SG_ SEC_STAT : 0|8@1+ (1,0) [0|0] "" Audio_Interface_Module

BO_ 718 BluetoothPairCodeAscii: 8 Bluetooth_Phone_Module
   SG_ BPM_MESSAGE0 : 0|8@4- (1,0) [0|255] "" Front_Display_Interface_Module
   SG_ BPM_MESSAGE1 : 8|8@4- (1,0) [0|255] "" Front_Display_Interface_Module
   SG_ BPM_MESSAGE2 : 16|8@4- (1,0) [0|255] "" Front_Display_Interface_Module
   SG_ BPM_MESSAGE3 : 24|8@4- (1,0) [0|255] "" Front_Display_Interface_Module
   SG_ BPM_MESSAGE4 : 32|8@4- (1,0) [0|255] "" Front_Display_Interface_Module
   SG_ BPM_MESSAGE5 : 40|8@4- (1,0) [0|255] "" Front_Display_Interface_Module
   SG_ BPM_MESSAGE6 : 48|8@4- (1,0) [0|255] "" Front_Display_Interface_Module
   SG_ BPM_MESSAGE7 : 56|8@4- (1,0) [0|255] "" Front_Display_Interface_Module

BO_ 829 MSG1: 0 Audio_Control_Module

BO_ 832 RCM_STAT_DPLY_ENABLED_RCRD_MS: 8 Restraints_Control_Module
   SG_ SIGNAL47332 : 0|8@1+ (1,0) [0|255] "" Restraints_Control_Module

BA_DEF_ BO_ "GenMsgBackgroundColor" STRING ;
BA_DEF_ BO_ "GenMsgForegroundColor" STRING ;
BA_ "GenMsgBackgroundColor" BO_ 754 "#36896e";
BA_ "GenMsgBackgroundColor" BO_ 764 "#36896e";
BA_ "GenMsgBackgroundColor" BO_ 757 "#5dbc8b";
BA_ "GenMsgBackgroundColor" BO_ 519 "#0055ff";
BA_ "GenMsgBackgroundColor" BO_ 787 "#36896e";
BA_ "GenMsgBackgroundColor" BO_ 775 "#36896e";
BA_ "GenMsgBackgroundColor" BO_ 779 "#36896e";
BA_ "GenMsgBackgroundColor" BO_ 781 "#36896e";
BA_ "GenMsgBackgroundColor" BO_ 783 "#36896e";
BA_ "GenMsgBackgroundColor" BO_ 785 "#36896e";
BA_ "GenMsgBackgroundColor" BO_ 789 "#36896e";
BA_ "GenMsgBackgroundColor" BO_ 791 "#36896e";
BA_ "GenMsgBackgroundColor" BO_ 816 "#36896e";
BA_ "GenMsgBackgroundColor" BO_ 1030 "#36896e";
BA_ "GenMsgForegroundColor" BO_ 1033 "#aaaaff";
BA_ "GenMsgBackgroundColor" BO_ 1033 "#aa007f";
BA_ "GenMsgBackgroundColor" BO_ 1281 "#ff1433";
BA_ "GenMsgBackgroundColor" BO_ 1292 "#ff1433";
BA_ "GenMsgBackgroundColor" BO_ 1297 "#aaaaff";
BA_ "GenMsgBackgroundColor" BO_ 1345 "#aa5500";
BA_ "GenMsgBackgroundColor" BO_ 1365 "#aa0000";
BA_ "GenMsgBackgroundColor" BO_ 1372 "#ffaaff";
BA_ "GenMsgBackgroundColor" BO_ 1600 "#ff00ff";
BA_ "GenMsgBackgroundColor" BO_ 1782 "#ff0000";
BA_ "GenMsgBackgroundColor" BO_ 1788 "#55aa7f";
BA_ "GenMsgBackgroundColor" BO_ 1061 "#aaffff";
BA_ "GenMsgBackgroundColor" BO_ 1063 "#00ffff";
BA_ "GenMsgBackgroundColor" BO_ 1200 "#00aa7f";
BA_ "GenMsgForegroundColor" BO_ 1200 "#ffffff";
BA_ "GenMsgBackgroundColor" BO_ 742 "#bc0591";
BA_ "GenMsgBackgroundColor" BO_ 758 "#5dbc8b";
BA_ "GenMsgBackgroundColor" BO_ 864 "#00aa7f";
BA_DEF_DEF_ "GenMsgBackgroundColor" "#ffffff";
BA_DEF_DEF_ "GenMsgForegroundColor" "#000000";
CM_ BU_ Audio_Control_Module "ACM";
CM_ BU_ Audio_Interface_Module "AIM";
CM_ BU_ Bluetooth_Phone_Module "BPM";
CM_ BU_ Body_Electric_Module "BEM";
CM_ BU_ Front_Display_Interface_Module "FDIM";
CM_ BU_ HVAC_Integrated_Module "HIM";
CM_ BU_ Instrustment_Cluster "IC";
CM_ BU_ Parking_Aid_Module "PAM";
CM_ BU_ Powertrain_Control_Module "PCM";
CM_ BU_ Restraints_Control_Module "RCM";
CM_ BU_ Transmission_Control_Module "TCM";
CM_ BU_ On_Board_Diagnostics "OBDII";
CM_ BU_ Antilock_Braking_System "ABS";
CM_ BO_ 754 "AudioCurrentMediaMode";
CM_ SG_ 754 AudioVolumeLevel "Volume";
CM_ SG_ 754 SteeringWheelControlsLeft_ms "SteeringWheelControlsLeft_ms";
CM_ BO_ 764 "IccMediaControl";
CM_ SG_ 0 ABSR_O "1Antilock_Braking_System ABS Rear Outlet Valve Status";
CM_ BO_ 787 "Cabin Temperature Sensor";
CM_ SG_ 787 INTACTTEMP "Interior_Temperature_Sensor_-_Integral_to_ICC_INTACTTEMP_=_Message.Data[0]_=_Temperature_-_100_/_2_L";
CM_ BO_ 775 "ICC HVAC Buttons";
CM_ SG_ 775 IllumBatsaverRequest_MS_0x307_ "IllumBatsaverRequest_MS_0x307_";
CM_ BO_ 1782 "Passive Anti Theft System";
CM_ SG_ 1782 ImmobTransfer_PCM_1_to_8_PATS "PATS";
CM_ SG_ 1063 EngineCoolantTemperature "EngCoolantTempSense";
CM_ SG_ 1063 EngineOverheat "EngineOverheat";
CM_ SG_ 1063 OilPressureWarning "OilPressWarn";
CM_ SG_ 1063 ETC_Warning "ThrottleWarnETC";
CM_ SG_ 1063 FuelPulse "FuelPulse";
CM_ SG_ 1063 MIL_Lamp "MalfunctionIndicatorLamp";
CM_ SG_ 1063 AC_Pressure "acpress";
CM_ SG_ 1063 ImmobLamp "ImmobilisedLamp";
CM_ SG_ 1063 ODO_COUNT "odocount";
CM_ SG_ 1063 BatteryVoltage "RefVolt";
CM_ SG_ 1063 EngineSpeedCounter "EngineReferenceCounter";
CM_ SG_ 742 AudioTunedFreqency "AudioTunedFrequency_(Message.Data[0]_*_2_)_+_(Message.Data[1]_*_0.01)";
CM_ SG_ 758 RDS_MESSAGE0 "Radio_Data_Service_Station_Name";
CM_ SG_ 758 RDS_MESSAGE1 "Radio_Data_Service_Station_Name";
CM_ SG_ 758 RDS_MESSAGE2 "Radio_Data_Service_Station_Name";
CM_ SG_ 758 RDS_MESSAGE3 "Radio_Data_Service_Station_Name";
CM_ SG_ 758 RDS_MESSAGE4 "Radio_Data_Service_Station_Name";
CM_ SG_ 758 RDS_MESSAGE5 "Radio_Data_Service_Station_Name";
CM_ SG_ 758 RDS_MESSAGE6 "Radio_Data_Service_Station_Name";
CM_ SG_ 758 RDS_MESSAGE7 "Radio_Data_Service_Station_Name";
CM_ BO_ 714 "unsure of TX module";
CM_ BO_ 39321 "IPOD_";
VAL_ 754 AudioVolumeLevel 0 "Mute" 1 "Vol_Lvl_2" 2 "Vol_Lvl_4" 3 "Vol_Lvl_6" 4 "Vol_Lvl_8" 5 "Vol_Lvl_10" 6 "Vol_Lvl_12" 7 "Vol_Lvl_14" 8 "Vol_Lvl_16" 9 "Vol_Lvl_18" 10 "Vol_Lvl_20" 11 "Vol_Lvl_22" 12 "Vol_Lvl_24" 13 "Vol_Lvl_26" 14 "Vol_Lvl_28" 15 "Vol_Lvl_30";
VAL_ 754 AudioCurrentMediaMode 65 "AUX_MODE_ACTIVE" 69 "FM_AM_MODE_ACTIVE" 72 "AUDIO_OFF_STATE" 97 "SWC_PHONE_BTN_ACTIVE" 101 "SWC_PHONE_BTN_ACTIVE" 104 "SWC_PHONE_BTN_ACTIVE" 0 "No Description";
VAL_ 754 SteeringWheelControlsLeft_ms 8 "SEEK_BUTTON_ACTIVE" 9 "SEEK_BUTTON_ACTIVE" 12 "SEEK_BUTTON_ACTIVE" 16 "SEEK_BUTTON_ACTIVE" 17 "VOL_UP_BTN_ACTIVE" 18 "VOL_UP_BTN_ACTIVE" 20 "VOL_UP_BTN_ACTIVE" 24 "VOL_DOWN_BTN_ACTIVE" 25 "VOL_DOWN_BTN_ACTIVE" 0 "No Description";
VAL_ 756 RDS_MESSAGE0 48 "0" 49 "1" 50 "2" 51 "3" 52 "4" 53 "5" 54 "6" 55 "7" 56 "8" 57 "9" 58 "10" 59 "11" 60 "12" 61 "13" 62 "14" 63 "15" 65 "A" 66 "B" 67 "C" 68 "D" 69 "E" 70 "F" 71 "G" 72 "H" 73 "I" 74 "J" 75 "K" 76 "L" 77 "M" 78 "N" 79 "O" 80 "P" 81 "Q" 82 "R" 83 "S" 84 "T" 85 "U" 86 "V" 87 "W" 88 "X" 89 "Y" 90 "Z" 91 "a" 92 "b" 93 "c" 94 "d" 95 "e" 96 "f" 97 "g" 98 "h" 99 "i" 100 "j" 101 "l" 102 "m" 103 "n" 104 "o" 105 "p" 106 "q" 107 "r" 108 "s" 109 "t" 110 "u" 111 "v" 112 "w" 113 "x" 114 "y" 115 "z";
VAL_ 756 RDS_MESSAGE1 48 "0" 49 "1" 50 "2" 51 "3" 52 "4" 53 "5" 54 "6" 55 "7" 56 "8" 57 "9" 58 "10" 59 "11" 60 "12" 61 "13" 62 "14" 63 "15" 65 "A" 66 "B" 67 "C" 68 "D" 69 "E" 70 "F" 71 "G" 72 "H" 73 "I" 74 "J" 75 "K" 76 "L" 77 "M" 78 "N" 79 "O" 80 "P" 81 "Q" 82 "R" 83 "S" 84 "T" 85 "U" 86 "V" 87 "W" 88 "X" 89 "Y" 90 "Z" 91 "a" 92 "b" 93 "c" 94 "d" 95 "e" 96 "f" 97 "g" 98 "h" 99 "i" 100 "j" 101 "l" 102 "m" 103 "n" 104 "o" 105 "p" 106 "q" 107 "r" 108 "s" 109 "t" 110 "u" 111 "v" 112 "w" 113 "x" 114 "y" 115 "z";
VAL_ 756 RDS_MESSAGE2 48 "0" 49 "1" 50 "2" 51 "3" 52 "4" 53 "5" 54 "6" 55 "7" 56 "8" 57 "9" 58 "10" 59 "11" 60 "12" 61 "13" 62 "14" 63 "15" 65 "A" 66 "B" 67 "C" 68 "D" 69 "E" 70 "F" 71 "G" 72 "H" 73 "I" 74 "J" 75 "K" 76 "L" 77 "M" 78 "N" 79 "O" 80 "P" 81 "Q" 82 "R" 83 "S" 84 "T" 85 "U" 86 "V" 87 "W" 88 "X" 89 "Y" 90 "Z" 91 "a" 92 "b" 93 "c" 94 "d" 95 "e" 96 "f" 97 "g" 98 "h" 99 "i" 100 "j" 101 "l" 102 "m" 103 "n" 104 "o" 105 "p" 106 "q" 107 "r" 108 "s" 109 "t" 110 "u" 111 "v" 112 "w" 113 "x" 114 "y" 115 "z";
VAL_ 756 RDS_MESSAGE3 48 "0" 49 "1" 50 "2" 51 "3" 52 "4" 53 "5" 54 "6" 55 "7" 56 "8" 57 "9" 58 "10" 59 "11" 60 "12" 61 "13" 62 "14" 63 "15" 65 "A" 66 "B" 67 "C" 68 "D" 69 "E" 70 "F" 71 "G" 72 "H" 73 "I" 74 "J" 75 "K" 76 "L" 77 "M" 78 "N" 79 "O" 80 "P" 81 "Q" 82 "R" 83 "S" 84 "T" 85 "U" 86 "V" 87 "W" 88 "X" 89 "Y" 90 "Z" 91 "a" 92 "b" 93 "c" 94 "d" 95 "e" 96 "f" 97 "g" 98 "h" 99 "i" 100 "j" 101 "l" 102 "m" 103 "n" 104 "o" 105 "p" 106 "q" 107 "r" 108 "s" 109 "t" 110 "u" 111 "v" 112 "w" 113 "x" 114 "y" 115 "z";
VAL_ 756 RDS_MESSAGE4 48 "0" 49 "1" 50 "2" 51 "3" 52 "4" 53 "5" 54 "6" 55 "7" 56 "8" 57 "9" 58 "10" 59 "11" 60 "12" 61 "13" 62 "14" 63 "15" 65 "A" 66 "B" 67 "C" 68 "D" 69 "E" 70 "F" 71 "G" 72 "H" 73 "I" 74 "J" 75 "K" 76 "L" 77 "M" 78 "N" 79 "O" 80 "P" 81 "Q" 82 "R" 83 "S" 84 "T" 85 "U" 86 "V" 87 "W" 88 "X" 89 "Y" 90 "Z" 91 "a" 92 "b" 93 "c" 94 "d" 95 "e" 96 "f" 97 "g" 98 "h" 99 "i" 100 "j" 101 "l" 102 "m" 103 "n" 104 "o" 105 "p" 106 "q" 107 "r" 108 "s" 109 "t" 110 "u" 111 "v" 112 "w" 113 "x" 114 "y" 115 "z";
VAL_ 756 RDS_MESSAGE5 48 "0" 49 "1" 50 "2" 51 "3" 52 "4" 53 "5" 54 "6" 55 "7" 56 "8" 57 "9" 58 "10" 59 "11" 60 "12" 61 "13" 62 "14" 63 "15" 65 "A" 66 "B" 67 "C" 68 "D" 69 "E" 70 "F" 71 "G" 72 "H" 73 "I" 74 "J" 75 "K" 76 "L" 77 "M" 78 "N" 79 "O" 80 "P" 81 "Q" 82 "R" 83 "S" 84 "T" 85 "U" 86 "V" 87 "W" 88 "X" 89 "Y" 90 "Z" 91 "a" 92 "b" 93 "c" 94 "d" 95 "e" 96 "f" 97 "g" 98 "h" 99 "i" 100 "j" 101 "l" 102 "m" 103 "n" 104 "o" 105 "p" 106 "q" 107 "r" 108 "s" 109 "t" 110 "u" 111 "v" 112 "w" 113 "x" 114 "y" 115 "z";
VAL_ 756 RDS_MESSAGE6 48 "0" 49 "1" 50 "2" 51 "3" 52 "4" 53 "5" 54 "6" 55 "7" 56 "8" 57 "9" 58 "10" 59 "11" 60 "12" 61 "13" 62 "14" 63 "15" 65 "A" 66 "B" 67 "C" 68 "D" 69 "E" 70 "F" 71 "G" 72 "H" 73 "I" 74 "J" 75 "K" 76 "L" 77 "M" 78 "N" 79 "O" 80 "P" 81 "Q" 82 "R" 83 "S" 84 "T" 85 "U" 86 "V" 87 "W" 88 "X" 89 "Y" 90 "Z" 91 "a" 92 "b" 93 "c" 94 "d" 95 "e" 96 "f" 97 "g" 98 "h" 99 "i" 100 "j" 101 "l" 102 "m" 103 "n" 104 "o" 105 "p" 106 "q" 107 "r" 108 "s" 109 "t" 110 "u" 111 "v" 112 "w" 113 "x" 114 "y" 115 "z";
VAL_ 756 RDS_MESSAGE7 48 "0" 49 "1" 50 "2" 51 "3" 52 "4" 53 "5" 54 "6" 55 "7" 56 "8" 57 "9" 58 "10" 59 "11" 60 "12" 61 "13" 62 "14" 63 "15" 65 "A" 66 "B" 67 "C" 68 "D" 69 "E" 70 "F" 71 "G" 72 "H" 73 "I" 74 "J" 75 "K" 76 "L" 77 "M" 78 "N" 79 "O" 80 "P" 81 "Q" 82 "R" 83 "S" 84 "T" 85 "U" 86 "V" 87 "W" 88 "X" 89 "Y" 90 "Z" 91 "a" 92 "b" 93 "c" 94 "d" 95 "e" 96 "f" 97 "g" 98 "h" 99 "i" 100 "j" 101 "l" 102 "m" 103 "n" 104 "o" 105 "p" 106 "q" 107 "r" 108 "s" 109 "t" 110 "u" 111 "v" 112 "w" 113 "x" 114 "y" 115 "z";
VAL_ 757 RDS_MESSAGE0 48 "0" 49 "1" 50 "2" 51 "3" 52 "4" 53 "5" 54 "6" 55 "7" 56 "8" 57 "9" 58 "10" 59 "11" 60 "12" 61 "13" 62 "14" 63 "15" 65 "A" 66 "B" 67 "C" 68 "D" 69 "E" 70 "F" 71 "G" 72 "H" 73 "I" 74 "J" 75 "K" 76 "L" 77 "M" 78 "N" 79 "O" 80 "P" 81 "Q" 82 "R" 83 "S" 84 "T" 85 "U" 86 "V" 87 "W" 88 "X" 89 "Y" 90 "Z" 91 "a" 92 "b" 93 "c" 94 "d" 95 "e" 96 "f" 97 "g" 98 "h" 99 "i" 100 "j" 101 "l" 102 "m" 103 "n" 104 "o" 105 "p" 106 "q" 107 "r" 108 "s" 109 "t" 110 "u" 111 "v" 112 "w" 113 "x" 114 "y" 115 "z";
VAL_ 757 RDS_MESSAGE1 48 "0" 49 "1" 50 "2" 51 "3" 52 "4" 53 "5" 54 "6" 55 "7" 56 "8" 57 "9" 58 "10" 59 "11" 60 "12" 61 "13" 62 "14" 63 "15" 65 "A" 66 "B" 67 "C" 68 "D" 69 "E" 70 "F" 71 "G" 72 "H" 73 "I" 74 "J" 75 "K" 76 "L" 77 "M" 78 "N" 79 "O" 80 "P" 81 "Q" 82 "R" 83 "S" 84 "T" 85 "U" 86 "V" 87 "W" 88 "X" 89 "Y" 90 "Z" 91 "a" 92 "b" 93 "c" 94 "d" 95 "e" 96 "f" 97 "g" 98 "h" 99 "i" 100 "j" 101 "l" 102 "m" 103 "n" 104 "o" 105 "p" 106 "q" 107 "r" 108 "s" 109 "t" 110 "u" 111 "v" 112 "w" 113 "x" 114 "y" 115 "z";
VAL_ 757 RDS_MESSAGE2 48 "0" 49 "1" 50 "2" 51 "3" 52 "4" 53 "5" 54 "6" 55 "7" 56 "8" 57 "9" 58 "10" 59 "11" 60 "12" 61 "13" 62 "14" 63 "15" 65 "A" 66 "B" 67 "C" 68 "D" 69 "E" 70 "F" 71 "G" 72 "H" 73 "I" 74 "J" 75 "K" 76 "L" 77 "M" 78 "N" 79 "O" 80 "P" 81 "Q" 82 "R" 83 "S" 84 "T" 85 "U" 86 "V" 87 "W" 88 "X" 89 "Y" 90 "Z" 91 "a" 92 "b" 93 "c" 94 "d" 95 "e" 96 "f" 97 "g" 98 "h" 99 "i" 100 "j" 101 "l" 102 "m" 103 "n" 104 "o" 105 "p" 106 "q" 107 "r" 108 "s" 109 "t" 110 "u" 111 "v" 112 "w" 113 "x" 114 "y" 115 "z";
VAL_ 757 RDS_MESSAGE3 48 "0" 49 "1" 50 "2" 51 "3" 52 "4" 53 "5" 54 "6" 55 "7" 56 "8" 57 "9" 58 "10" 59 "11" 60 "12" 61 "13" 62 "14" 63 "15" 65 "A" 66 "B" 67 "C" 68 "D" 69 "E" 70 "F" 71 "G" 72 "H" 73 "I" 74 "J" 75 "K" 76 "L" 77 "M" 78 "N" 79 "O" 80 "P" 81 "Q" 82 "R" 83 "S" 84 "T" 85 "U" 86 "V" 87 "W" 88 "X" 89 "Y" 90 "Z" 91 "a" 92 "b" 93 "c" 94 "d" 95 "e" 96 "f" 97 "g" 98 "h" 99 "i" 100 "j" 101 "l" 102 "m" 103 "n" 104 "o" 105 "p" 106 "q" 107 "r" 108 "s" 109 "t" 110 "u" 111 "v" 112 "w" 113 "x" 114 "y" 115 "z";
VAL_ 757 RDS_MESSAGE4 48 "0" 49 "1" 50 "2" 51 "3" 52 "4" 53 "5" 54 "6" 55 "7" 56 "8" 57 "9" 58 "10" 59 "11" 60 "12" 61 "13" 62 "14" 63 "15" 65 "A" 66 "B" 67 "C" 68 "D" 69 "E" 70 "F" 71 "G" 72 "H" 73 "I" 74 "J" 75 "K" 76 "L" 77 "M" 78 "N" 79 "O" 80 "P" 81 "Q" 82 "R" 83 "S" 84 "T" 85 "U" 86 "V" 87 "W" 88 "X" 89 "Y" 90 "Z" 91 "a" 92 "b" 93 "c" 94 "d" 95 "e" 96 "f" 97 "g" 98 "h" 99 "i" 100 "j" 101 "l" 102 "m" 103 "n" 104 "o" 105 "p" 106 "q" 107 "r" 108 "s" 109 "t" 110 "u" 111 "v" 112 "w" 113 "x" 114 "y" 115 "z";
VAL_ 757 RDS_MESSAGE5 48 "0" 49 "1" 50 "2" 51 "3" 52 "4" 53 "5" 54 "6" 55 "7" 56 "8" 57 "9" 58 "10" 59 "11" 60 "12" 61 "13" 62 "14" 63 "15" 65 "A" 66 "B" 67 "C" 68 "D" 69 "E" 70 "F" 71 "G" 72 "H" 73 "I" 74 "J" 75 "K" 76 "L" 77 "M" 78 "N" 79 "O" 80 "P" 81 "Q" 82 "R" 83 "S" 84 "T" 85 "U" 86 "V" 87 "W" 88 "X" 89 "Y" 90 "Z" 91 "a" 92 "b" 93 "c" 94 "d" 95 "e" 96 "f" 97 "g" 98 "h" 99 "i" 100 "j" 101 "l" 102 "m" 103 "n" 104 "o" 105 "p" 106 "q" 107 "r" 108 "s" 109 "t" 110 "u" 111 "v" 112 "w" 113 "x" 114 "y" 115 "z";
VAL_ 757 RDS_MESSAGE6 48 "0" 49 "1" 50 "2" 51 "3" 52 "4" 53 "5" 54 "6" 55 "7" 56 "8" 57 "9" 58 "10" 59 "11" 60 "12" 61 "13" 62 "14" 63 "15" 65 "A" 66 "B" 67 "C" 68 "D" 69 "E" 70 "F" 71 "G" 72 "H" 73 "I" 74 "J" 75 "K" 76 "L" 77 "M" 78 "N" 79 "O" 80 "P" 81 "Q" 82 "R" 83 "S" 84 "T" 85 "U" 86 "V" 87 "W" 88 "X" 89 "Y" 90 "Z" 91 "a" 92 "b" 93 "c" 94 "d" 95 "e" 96 "f" 97 "g" 98 "h" 99 "i" 100 "j" 101 "l" 102 "m" 103 "n" 104 "o" 105 "p" 106 "q" 107 "r" 108 "s" 109 "t" 110 "u" 111 "v" 112 "w" 113 "x" 114 "y" 115 "z";
VAL_ 757 RDS_MESSAGE7 48 "0" 49 "1" 50 "2" 51 "3" 52 "4" 53 "5" 54 "6" 55 "7" 56 "8" 57 "9" 58 "10" 59 "11" 60 "12" 61 "13" 62 "14" 63 "15" 65 "A" 66 "B" 67 "C" 68 "D" 69 "E" 70 "F" 71 "G" 72 "H" 73 "I" 74 "J" 75 "K" 76 "L" 77 "M" 78 "N" 79 "O" 80 "P" 81 "Q" 82 "R" 83 "S" 84 "T" 85 "U" 86 "V" 87 "W" 88 "X" 89 "Y" 90 "Z" 91 "a" 92 "b" 93 "c" 94 "d" 95 "e" 96 "f" 97 "g" 98 "h" 99 "i" 100 "j" 101 "l" 102 "m" 103 "n" 104 "o" 105 "p" 106 "q" 107 "r" 108 "s" 109 "t" 110 "u" 111 "v" 112 "w" 113 "x" 114 "y" 115 "z";
VAL_ 519 EngineRPM_HS 0 "";
VAL_ 519 ManifoldThrottlePosition 0 "Idle_Throttle" 200 "Full_Throttle";
VAL_ 0 ABSLF_I 0 "1Antilock_Braking_System " 0 "1Antilock_Braking_System Left Front Inlet Valve State";
VAL_ 0 ABSLF_O 0 "1Antilock_Braking_System Left Front Outlet Valve State";
VAL_ 0 ABSLR_I 0 "1Antilock_Braking_System Left Rear Inlet Valve State";
VAL_ 0 ABSLR_O 0 "1Antilock_Braking_System Left Rear Outlet Valve State";
VAL_ 0 ABSPMPRLY 0 "Antilock_Braking_System ABS Pump Motor Relay";
VAL_ 0 ABSRF_I 0 "1Antilock_Braking_System Right Front Inlet Valve State";
VAL_ 0 ABSRF_O 0 "1Antilock_Braking_System Right Front Outlet Valve State";
VAL_ 0 ABSRR_I 0 "1Antilock_Braking_System Right Rear Inlet Valve State";
VAL_ 0 ABSR_I 0 "1Antilock_Braking_System ABS Rear Inlet Valve Status";
VAL_ 0 ABSR_O 0 "1Antilock_Braking_System ABS Rear Outlet Valve Status";
VAL_ 0 ABSVLVRLY 0 "Antilock_Braking_System ABS Valve Control Relay";
VAL_ 0 ABS_BYTE 0 "Antilock_Braking_System 204 ABS Process Byte";
VAL_ 0 ABS_STAT 0 "Antilock_Braking_System Diagnostic ECU Operating States";
VAL_ 0 BOO_ABS 0 "Antilock_Braking_System Inactive Brake ON/OFF";
VAL_ 0 BRAKPRES 0 "Antilock_Braking_System 0.0 kPa Brake Fluid Line Hydraulic Pressure";
VAL_ 0 CCNTABS 0 "Antilock_Braking_System0 Continuous Codes";
VAL_ 0 DISABLE_SS 0 "Antilock_Braking_System No Disable Safety Software";
VAL_ 0 HDC_ENABLE 0 "Antilock_Braking_System Inactive HDC Enable";
VAL_ 0 HDC_SW 0 "1Antilock_Braking_System Inactive HDC Switch Status";
VAL_ 0 Ignition 0 " Antilock_Braking_System 12.18 V Ignition";
VAL_ 0 LAT_ACCL 0 " Antilock_Braking_System -0.02 G ABS Lateral Acceleration Rate";
VAL_ 0 LF_WSPD 0 " Antilock_Braking_System 2.0 km/h Left front wheel speed sensor";
VAL_ 0 LR_WSPD 0 " Antilock_Braking_System 2.0 km/h Left rear wheel speed sensor";
VAL_ 0 PMPSTAT 0 " Antilock_Braking_System Inactive ABS Pump Motor Status";
VAL_ 0 PRK_BRAKE 0 "Antilock_Braking_SystemInactive Parking brake Switch";
VAL_ 0 RF_WSPD 0 "Antilock_Braking_System 2.0 km/h Right front wheel speed sensor";
VAL_ 0 RR_WSPD 0 "Antilock_Braking_System 2.0 km/h Right rear wheel speed sensor";
VAL_ 0 STEER_ANGL 0 " Antilock_Braking_System -4.10 ° Steering wheel angle sensor";
VAL_ 0 TCSPRI1 0 "Antilock_Braking_System Inactive TCS Priming Valve 1";
VAL_ 0 TCSSWI1 0 "Antilock_Braking_System Inactive TCS Switching Valve 1";
VAL_ 0 TCSSWI2 0 "Antilock_Braking_System Inactive TCS Switching Valve 2";
VAL_ 0 TCYC_FS 0 "Antilock_Braking_System Off Traction control system";
VAL_ 0 TCYC_SW 0 "Antilock_Braking_System Up Traction Control Switch Status";
VAL_ 0 YAW_RATE 0 " Antilock_Braking_System -0 1/min ABS Yaw Rate Value";
VAL_ 787 INTACTTEMP 0 "No_Data" 1 "" 2 "" 125 "CabinTemperatureSensor";
VAL_ 775 IllumBatsaverRequest_MS_0x307_ 0 "";
VAL_ 775 IllumBatsaverRequest_MS_0x307_99 0 "";
VAL_ 775 IllumBatsaverRequest_MS_0x307_9916 0 "";
VAL_ 781 CD_TrackNumber 0 "No Description";
VAL_ 781 CD_Type 0 "" 0 "No Description";
VAL_ 781 CD_PlayingNow 0 "No Description";
VAL_ 789 CycleLockSetting 4 "CycleTwoStageUnlock" 8 "CycleConfirmUnlockIndicators" 64 "Cycle_Drive_Away_Locking" 128 "CycleConfirmUnlockIndicators";
VAL_ 789 CabLightSetting 64 "CabLightsResetSettings" 32 "CabLightsOnUnlock" 128 "CabLightsOnDoorOpen";
VAL_ 1030 SeatBeltStatusFrontRight 0 "No Description";
VAL_ 1030 SeatBeltStatusFrontLeft 0 "No Description";
VAL_ 1030 SeatBeltStatusRearLeft 0 "No Description";
VAL_ 1030 SeatBeltStatusRearRight 0 "No Description";
VAL_ 1030 IgnitionState 1 "IgnitionOff" 2 "AccessoryOn" 4 "IgnitionOn" 0 "No Description";
VAL_ 1030 InteriorLightStatus 8 "InteriorLightsOn" 0 "InteriorLightsOff";
VAL_ 1600 ManualTrans 0 "DISPLAY_PRNDL_ON_CLUSTER_LCD" 1 "REMOVE_PRNDL_FROM_CLUSTER_LCD" 0 "";
VAL_ 1782 ImmobTransfer_PCM_1_to_8_PATS 0 "No Description";
VAL_ 301 BrakeHardwareStatus 0 "BrakeOff" 1 "BrakeOn";
VAL_ 1063 EngineCoolantTemperature 0 "EngCoolTemp";
VAL_ 1063 OilPressureWarning 0 "No Description";
VAL_ 1063 BatteryVoltage 0 "LowVoltage" 0 "Voltage" 0 "HighVoltage";
VAL_ 1079 ParkBrakeOn_HS 1 "HandBrakeOff" 17 "HandBrakeOn";
VAL_ 1200 WhlRr_W_Meas 32767 "Fault" 32766 "Unknown";
VAL_ 1200 WhlRl_W_Meas 32767 "Fault" 32766 "Unknown";
VAL_ 1200 WhlFr_W_Meas 32767 "Fault" 32766 "Unknown";
VAL_ 1200 WhlFl_W_Meas 32767 "Fault" 32766 "Unknown";
VAL_ 1571 EngineCapacityLitres 54 "5.4_Litre" 18 "" 34 "";
VAL_ 1571 EngineAspirationFuelType 18 "NaturallyAspiratedEngine" 34 "TurboChargedEngine" 0 "SuperChargedEngine" 0 "Unknown" 0 "No Description";
VAL_ 1571 EnginePeakTorque 125 "500_Newton_Metres";
VAL_ 742 AudioTunedFreqency 0 "" 50 "100" 47 "94" 46 "";
VAL_ 742 AudioFMFrequencyStep 0 "AudioFMFrequencyStep_(Message.Data[1]_*_0.01)" 2 "" 18 "No Description";
VAL_ 742 AudioTunerBandPreset 0 "AM_Radio";
VAL_ 742 RDS_PSN_State 0 "No Description";
VAL_ 758 RDS_MESSAGE0 48 "0" 49 "1" 50 "2" 51 "3" 52 "4" 53 "5" 54 "6" 55 "7" 56 "8" 57 "9" 58 "10" 59 "11" 60 "12" 61 "13" 62 "14" 63 "15" 65 "A" 66 "B" 67 "C" 68 "D" 69 "E" 70 "F" 71 "G" 72 "H" 73 "I" 74 "J" 75 "K" 76 "L" 77 "M" 78 "N" 79 "O" 80 "P" 81 "Q" 82 "R" 83 "S" 84 "T" 85 "U" 86 "V" 87 "W" 88 "X" 89 "Y" 90 "Z" 91 "a" 92 "b" 93 "c" 94 "d" 95 "e" 96 "f" 97 "g" 98 "h" 99 "i" 100 "j" 101 "l" 102 "m" 103 "n" 104 "o" 105 "p" 106 "q" 107 "r" 108 "s" 109 "t" 110 "u" 111 "v" 112 "w" 113 "x" 114 "y" 115 "z";
VAL_ 758 RDS_MESSAGE1 48 "0" 49 "1" 50 "2" 51 "3" 52 "4" 53 "5" 54 "6" 55 "7" 56 "8" 57 "9" 58 "10" 59 "11" 60 "12" 61 "13" 62 "14" 63 "15" 65 "A" 66 "B" 67 "C" 68 "D" 69 "E" 70 "F" 71 "G" 72 "H" 73 "I" 74 "J" 75 "K" 76 "L" 77 "M" 78 "N" 79 "O" 80 "P" 81 "Q" 82 "R" 83 "S" 84 "T" 85 "U" 86 "V" 87 "W" 88 "X" 89 "Y" 90 "Z" 91 "a" 92 "b" 93 "c" 94 "d" 95 "e" 96 "f" 97 "g" 98 "h" 99 "i" 100 "j" 101 "l" 102 "m" 103 "n" 104 "o" 105 "p" 106 "q" 107 "r" 108 "s" 109 "t" 110 "u" 111 "v" 112 "w" 113 "x" 114 "y" 115 "z";
VAL_ 758 RDS_MESSAGE2 48 "0" 49 "1" 50 "2" 51 "3" 52 "4" 53 "5" 54 "6" 55 "7" 56 "8" 57 "9" 58 "10" 59 "11" 60 "12" 61 "13" 62 "14" 63 "15" 65 "A" 66 "B" 67 "C" 68 "D" 69 "E" 70 "F" 71 "G" 72 "H" 73 "I" 74 "J" 75 "K" 76 "L" 77 "M" 78 "N" 79 "O" 80 "P" 81 "Q" 82 "R" 83 "S" 84 "T" 85 "U" 86 "V" 87 "W" 88 "X" 89 "Y" 90 "Z" 91 "a" 92 "b" 93 "c" 94 "d" 95 "e" 96 "f" 97 "g" 98 "h" 99 "i" 100 "j" 101 "l" 102 "m" 103 "n" 104 "o" 105 "p" 106 "q" 107 "r" 108 "s" 109 "t" 110 "u" 111 "v" 112 "w" 113 "x" 114 "y" 115 "z";
VAL_ 758 RDS_MESSAGE3 48 "0" 49 "1" 50 "2" 51 "3" 52 "4" 53 "5" 54 "6" 55 "7" 56 "8" 57 "9" 58 "10" 59 "11" 60 "12" 61 "13" 62 "14" 63 "15" 65 "A" 66 "B" 67 "C" 68 "D" 69 "E" 70 "F" 71 "G" 72 "H" 73 "I" 74 "J" 75 "K" 76 "L" 77 "M" 78 "N" 79 "O" 80 "P" 81 "Q" 82 "R" 83 "S" 84 "T" 85 "U" 86 "V" 87 "W" 88 "X" 89 "Y" 90 "Z" 91 "a" 92 "b" 93 "c" 94 "d" 95 "e" 96 "f" 97 "g" 98 "h" 99 "i" 100 "j" 101 "l" 102 "m" 103 "n" 104 "o" 105 "p" 106 "q" 107 "r" 108 "s" 109 "t" 110 "u" 111 "v" 112 "w" 113 "x" 114 "y" 115 "z";
VAL_ 758 RDS_MESSAGE4 48 "0" 49 "1" 50 "2" 51 "3" 52 "4" 53 "5" 54 "6" 55 "7" 56 "8" 57 "9" 58 "10" 59 "11" 60 "12" 61 "13" 62 "14" 63 "15" 65 "A" 66 "B" 67 "C" 68 "D" 69 "E" 70 "F" 71 "G" 72 "H" 73 "I" 74 "J" 75 "K" 76 "L" 77 "M" 78 "N" 79 "O" 80 "P" 81 "Q" 82 "R" 83 "S" 84 "T" 85 "U" 86 "V" 87 "W" 88 "X" 89 "Y" 90 "Z" 91 "a" 92 "b" 93 "c" 94 "d" 95 "e" 96 "f" 97 "g" 98 "h" 99 "i" 100 "j" 101 "l" 102 "m" 103 "n" 104 "o" 105 "p" 106 "q" 107 "r" 108 "s" 109 "t" 110 "u" 111 "v" 112 "w" 113 "x" 114 "y" 115 "z";
VAL_ 758 RDS_MESSAGE5 48 "0" 49 "1" 50 "2" 51 "3" 52 "4" 53 "5" 54 "6" 55 "7" 56 "8" 57 "9" 58 "10" 59 "11" 60 "12" 61 "13" 62 "14" 63 "15" 65 "A" 66 "B" 67 "C" 68 "D" 69 "E" 70 "F" 71 "G" 72 "H" 73 "I" 74 "J" 75 "K" 76 "L" 77 "M" 78 "N" 79 "O" 80 "P" 81 "Q" 82 "R" 83 "S" 84 "T" 85 "U" 86 "V" 87 "W" 88 "X" 89 "Y" 90 "Z" 91 "a" 92 "b" 93 "c" 94 "d" 95 "e" 96 "f" 97 "g" 98 "h" 99 "i" 100 "j" 101 "l" 102 "m" 103 "n" 104 "o" 105 "p" 106 "q" 107 "r" 108 "s" 109 "t" 110 "u" 111 "v" 112 "w" 113 "x" 114 "y" 115 "z";
VAL_ 758 RDS_MESSAGE6 48 "0" 49 "1" 50 "2" 51 "3" 52 "4" 53 "5" 54 "6" 55 "7" 56 "8" 57 "9" 58 "10" 59 "11" 60 "12" 61 "13" 62 "14" 63 "15" 65 "A" 66 "B" 67 "C" 68 "D" 69 "E" 70 "F" 71 "G" 72 "H" 73 "I" 74 "J" 75 "K" 76 "L" 77 "M" 78 "N" 79 "O" 80 "P" 81 "Q" 82 "R" 83 "S" 84 "T" 85 "U" 86 "V" 87 "W" 88 "X" 89 "Y" 90 "Z" 91 "a" 92 "b" 93 "c" 94 "d" 95 "e" 96 "f" 97 "g" 98 "h" 99 "i" 100 "j" 101 "l" 102 "m" 103 "n" 104 "o" 105 "p" 106 "q" 107 "r" 108 "s" 109 "t" 110 "u" 111 "v" 112 "w" 113 "x" 114 "y" 115 "z";
VAL_ 758 RDS_MESSAGE7 48 "0" 49 "1" 50 "2" 51 "3" 52 "4" 53 "5" 54 "6" 55 "7" 56 "8" 57 "9" 58 "10" 59 "11" 60 "12" 61 "13" 62 "14" 63 "15" 65 "A" 66 "B" 67 "C" 68 "D" 69 "E" 70 "F" 71 "G" 72 "H" 73 "I" 74 "J" 75 "K" 76 "L" 77 "M" 78 "N" 79 "O" 80 "P" 81 "Q" 82 "R" 83 "S" 84 "T" 85 "U" 86 "V" 87 "W" 88 "X" 89 "Y" 90 "Z" 91 "a" 92 "b" 93 "c" 94 "d" 95 "e" 96 "f" 97 "g" 98 "h" 99 "i" 100 "j" 101 "l" 102 "m" 103 "n" 104 "o" 105 "p" 106 "q" 107 "r" 108 "s" 109 "t" 110 "u" 111 "v" 112 "w" 113 "x" 114 "y" 115 "z";
VAL_ 714 BTH_CONTD 0 "BluetoothReceptionSignalStrength";
VAL_ 714 CCNT 0 "NumberOfContinuousTroubleCodesSet";
VAL_ 714 ECU 0 "ECUOperatingStates";
VAL_ 714 ONDEMDTC 0 "NumberOfOnDemandDTCs";
VAL_ 714 SEC_STAT_BPM 0 "SecurityStatus";
VAL_ 864 PARK_SYS 0 "ParkingAidSystemInactive" 5 "ParkingAidSystemActive";
VAL_ 864 RC_DIST 0 "EchoValueForRightCornerSensor";
VAL_ 864 REAR_SENS 0 "ParkingAidRearSensorStatus" 255 "Active";
VAL_ 864 REAR_TONE 0 "ParkingAidSounder";
VAL_ 864 RM_DIST 0 "EchoValueForRightMiddleSensor";
VAL_ 864 SENSOR_SPL_V 0 "SensorSupplyVoltage";
VAL_ 864 SPEED_DEACT 0 "VehicleSpeedAboveDeactivationThreshold";
VAL_ 864 SYS_OZ 0 "SystemOutputZone";
VAL_ 864 TRAILINS 0 "TrailerInstalled";
VAL_ 864 TRANSRV 0 "TransmissionInREVERSE";
VAL_ 864 VBAT 0 "BatteryVoltage";
VAL_ 296 IllumLevelSwitch 1 "HeadLightsOnAuto" 2 "HeadLightsOn" 6 "FogLightsOn" 14 "HighBeamsOn";
VAL_ 296 TurnStalkSwitchSatus 8 "IndicatingLeft" 16 "IndicatingRight";
VAL_ 851 VentStatus 43 "Foot_Vent_Open_Cabin" 47 "Window_Foot_Vent_Open_Cabin" 79 "Window_and_Feet_Vents,_Close_Cabin" 91 "Face,_Foot,_Close_Cabin" 59 "Face,_Foot,_Open_Cabin" 51 "Face,_Open_Cabin" 83 "Face,_Close_Cabin" 38 "Window,_Auto_Fan" 131 "A/C_Off,_Open_Cabin" 139 "A/C_Off,_Foot_Vents,_Open_Cabin" 143 "A/C_Off,_Foot_and_Window_Vents,_Open_Cabin" 155 "A/C_Off,_Foot_and_Face_Vents,_Open_Cabin" 166 "A/C_Off,_Window_Vents,_Open_Cabin" 167 "A/C_Off,_Manual_Fan,_Open_Cabin";
VAL_ 718 BPM_MESSAGE0 48 "0" 49 "1" 50 "2" 51 "3" 52 "4" 53 "5" 54 "6" 55 "7" 56 "8" 57 "9" 58 "10" 59 "11" 60 "12" 61 "13" 62 "14" 63 "15" 65 "A" 66 "B" 67 "C" 68 "D" 69 "E" 70 "F" 71 "G" 72 "H" 73 "I" 74 "J" 75 "K" 76 "L" 77 "M" 78 "N" 79 "O" 80 "P" 81 "Q" 82 "R" 83 "S" 84 "T" 85 "U" 86 "V" 87 "W" 88 "X" 89 "Y" 90 "Z" 91 "a" 92 "b" 93 "c" 94 "d" 95 "e" 96 "f" 97 "g" 98 "h" 99 "i" 100 "j" 101 "l" 102 "m" 103 "n" 104 "o" 105 "p" 106 "q" 107 "r" 108 "s" 109 "t" 110 "u" 111 "v" 112 "w" 113 "x" 114 "y" 115 "z";
VAL_ 718 BPM_MESSAGE1 48 "0" 49 "1" 50 "2" 51 "3" 52 "4" 53 "5" 54 "6" 55 "7" 56 "8" 57 "9" 58 "10" 59 "11" 60 "12" 61 "13" 62 "14" 63 "15" 65 "A" 66 "B" 67 "C" 68 "D" 69 "E" 70 "F" 71 "G" 72 "H" 73 "I" 74 "J" 75 "K" 76 "L" 77 "M" 78 "N" 79 "O" 80 "P" 81 "Q" 82 "R" 83 "S" 84 "T" 85 "U" 86 "V" 87 "W" 88 "X" 89 "Y" 90 "Z" 91 "a" 92 "b" 93 "c" 94 "d" 95 "e" 96 "f" 97 "g" 98 "h" 99 "i" 100 "j" 101 "l" 102 "m" 103 "n" 104 "o" 105 "p" 106 "q" 107 "r" 108 "s" 109 "t" 110 "u" 111 "v" 112 "w" 113 "x" 114 "y" 115 "z";
VAL_ 718 BPM_MESSAGE2 48 "0" 49 "1" 50 "2" 51 "3" 52 "4" 53 "5" 54 "6" 55 "7" 56 "8" 57 "9" 58 "10" 59 "11" 60 "12" 61 "13" 62 "14" 63 "15" 65 "A" 66 "B" 67 "C" 68 "D" 69 "E" 70 "F" 71 "G" 72 "H" 73 "I" 74 "J" 75 "K" 76 "L" 77 "M" 78 "N" 79 "O" 80 "P" 81 "Q" 82 "R" 83 "S" 84 "T" 85 "U" 86 "V" 87 "W" 88 "X" 89 "Y" 90 "Z" 91 "a" 92 "b" 93 "c" 94 "d" 95 "e" 96 "f" 97 "g" 98 "h" 99 "i" 100 "j" 101 "l" 102 "m" 103 "n" 104 "o" 105 "p" 106 "q" 107 "r" 108 "s" 109 "t" 110 "u" 111 "v" 112 "w" 113 "x" 114 "y" 115 "z";
VAL_ 718 BPM_MESSAGE3 48 "0" 49 "1" 50 "2" 51 "3" 52 "4" 53 "5" 54 "6" 55 "7" 56 "8" 57 "9" 58 "10" 59 "11" 60 "12" 61 "13" 62 "14" 63 "15" 65 "A" 66 "B" 67 "C" 68 "D" 69 "E" 70 "F" 71 "G" 72 "H" 73 "I" 74 "J" 75 "K" 76 "L" 77 "M" 78 "N" 79 "O" 80 "P" 81 "Q" 82 "R" 83 "S" 84 "T" 85 "U" 86 "V" 87 "W" 88 "X" 89 "Y" 90 "Z" 91 "a" 92 "b" 93 "c" 94 "d" 95 "e" 96 "f" 97 "g" 98 "h" 99 "i" 100 "j" 101 "l" 102 "m" 103 "n" 104 "o" 105 "p" 106 "q" 107 "r" 108 "s" 109 "t" 110 "u" 111 "v" 112 "w" 113 "x" 114 "y" 115 "z";
VAL_ 718 BPM_MESSAGE4 48 "0" 49 "1" 50 "2" 51 "3" 52 "4" 53 "5" 54 "6" 55 "7" 56 "8" 57 "9" 58 "10" 59 "11" 60 "12" 61 "13" 62 "14" 63 "15" 65 "A" 66 "B" 67 "C" 68 "D" 69 "E" 70 "F" 71 "G" 72 "H" 73 "I" 74 "J" 75 "K" 76 "L" 77 "M" 78 "N" 79 "O" 80 "P" 81 "Q" 82 "R" 83 "S" 84 "T" 85 "U" 86 "V" 87 "W" 88 "X" 89 "Y" 90 "Z" 91 "a" 92 "b" 93 "c" 94 "d" 95 "e" 96 "f" 97 "g" 98 "h" 99 "i" 100 "j" 101 "l" 102 "m" 103 "n" 104 "o" 105 "p" 106 "q" 107 "r" 108 "s" 109 "t" 110 "u" 111 "v" 112 "w" 113 "x" 114 "y" 115 "z";
VAL_ 718 BPM_MESSAGE5 48 "0" 49 "1" 50 "2" 51 "3" 52 "4" 53 "5" 54 "6" 55 "7" 56 "8" 57 "9" 58 "10" 59 "11" 60 "12" 61 "13" 62 "14" 63 "15" 65 "A" 66 "B" 67 "C" 68 "D" 69 "E" 70 "F" 71 "G" 72 "H" 73 "I" 74 "J" 75 "K" 76 "L" 77 "M" 78 "N" 79 "O" 80 "P" 81 "Q" 82 "R" 83 "S" 84 "T" 85 "U" 86 "V" 87 "W" 88 "X" 89 "Y" 90 "Z" 91 "a" 92 "b" 93 "c" 94 "d" 95 "e" 96 "f" 97 "g" 98 "h" 99 "i" 100 "j" 101 "l" 102 "m" 103 "n" 104 "o" 105 "p" 106 "q" 107 "r" 108 "s" 109 "t" 110 "u" 111 "v" 112 "w" 113 "x" 114 "y" 115 "z";
VAL_ 718 BPM_MESSAGE6 48 "0" 49 "1" 50 "2" 51 "3" 52 "4" 53 "5" 54 "6" 55 "7" 56 "8" 57 "9" 58 "10" 59 "11" 60 "12" 61 "13" 62 "14" 63 "15" 65 "A" 66 "B" 67 "C" 68 "D" 69 "E" 70 "F" 71 "G" 72 "H" 73 "I" 74 "J" 75 "K" 76 "L" 77 "M" 78 "N" 79 "O" 80 "P" 81 "Q" 82 "R" 83 "S" 84 "T" 85 "U" 86 "V" 87 "W" 88 "X" 89 "Y" 90 "Z" 91 "a" 92 "b" 93 "c" 94 "d" 95 "e" 96 "f" 97 "g" 98 "h" 99 "i" 100 "j" 101 "l" 102 "m" 103 "n" 104 "o" 105 "p" 106 "q" 107 "r" 108 "s" 109 "t" 110 "u" 111 "v" 112 "w" 113 "x" 114 "y" 115 "z";
VAL_ 718 BPM_MESSAGE7 48 "0" 49 "1" 50 "2" 51 "3" 52 "4" 53 "5" 54 "6" 55 "7" 56 "8" 57 "9" 58 "10" 59 "11" 60 "12" 61 "13" 62 "14" 63 "15" 65 "A" 66 "B" 67 "C" 68 "D" 69 "E" 70 "F" 71 "G" 72 "H" 73 "I" 74 "J" 75 "K" 76 "L" 77 "M" 78 "N" 79 "O" 80 "P" 81 "Q" 82 "R" 83 "S" 84 "T" 85 "U" 86 "V" 87 "W" 88 "X" 89 "Y" 90 "Z" 91 "a" 92 "b" 93 "c" 94 "d" 95 "e" 96 "f" 97 "g" 98 "h" 99 "i" 100 "j" 101 "l" 102 "m" 103 "n" 104 "o" 105 "p" 106 "q" 107 "r" 108 "s" 109 "t" 110 "u" 111 "v" 112 "w" 113 "x" 114 "y" 115 "z";
